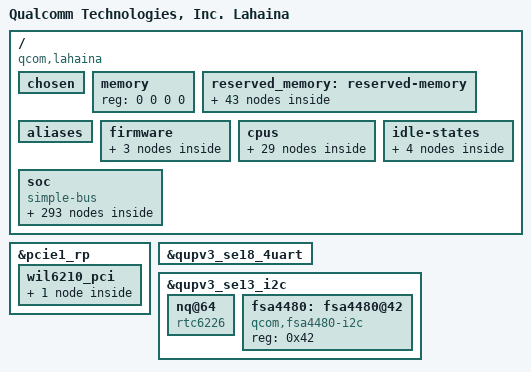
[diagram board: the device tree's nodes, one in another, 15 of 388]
// SPDX-License-Identifier: BSD-3-Clause
/*
 * Copyright (c) Qualcomm Technologies, Inc. and/or its subsidiaries.
 */

#include <dt-bindings/clock/qcom,aop-qmp.h>
#include <dt-bindings/clock/qcom,camcc-sm8350.h>
#include <dt-bindings/clock/qcom,dispcc-sm8350.h>
#include <dt-bindings/clock/qcom,gcc-sm8350.h>
#include <dt-bindings/clock/qcom,gpucc-sm8350.h>
#include <dt-bindings/clock/qcom,rpmh.h>
#include <dt-bindings/clock/qcom,sm8350-videocc.h>
#include <dt-bindings/interrupt-controller/arm-gic.h>
#include <dt-bindings/interconnect/qcom,icc.h>
#include <dt-bindings/interconnect/qcom,lahaina.h>
#include <dt-bindings/soc/qcom,ipcc.h>
#include <dt-bindings/soc/qcom,dcc_v2.h>
#include <dt-bindings/soc/qcom,rpmh-rsc.h>
#include <dt-bindings/spmi/spmi.h>
#include <dt-bindings/regulator/qcom,rpmh-regulator-levels.h>
#include <dt-bindings/gpio/gpio.h>


/ {
	model = "Qualcomm Technologies, Inc. Lahaina";
	compatible = "qcom,lahaina";
	qcom,msm-id = <415 0x10000>, <456 0x10000>, <501 0x10000>;
	interrupt-parent = <&intc>;

	#address-cells = <2>;
	#size-cells = <2>;

	chosen {
		bootargs = "loglevel=6 log_buf_len=512K rcupdate.rcu_expedited=1 printk.console_no_auto_verbose=1 rcu_nocbs=0-7 kpti=0 cpufreq.default_governor=performance pcie_ports=compat fw_devlink.strict=1 android_arch_task_struct_size=512 arm64.nosme sysctl.kernel.sched_pelt_multiplier=4 no-steal-acc swiotlb=0 loop.max_part=7 irqaffinity=0-1 kasan=off cgroup_disable=pressure sysctl.kernel.panic_on_rcu_stall=1 ftrace_dump_on_oops restrict_cma_redirect=false slub_debug=-";
		stdout-path = "/soc/qcom,qupv3_0_geni_se@9c0000/qcom,qup_uart@98c000:115200n8";
	};

	memory { device_type = "memory"; reg = <0 0 0 0>; };
	reserved_memory: reserved-memory { };

	aliases: aliases {
		ufshc1 = &ufshc_mem; /* Embedded UFS Slot */
		sdhc1 = &sdhc_2; /* SDC2 SD card slot */
		serial0 = &qupv3_se3_2uart;
		hsuart0 = &qupv3_se18_4uart;
		pci-domain0 = &pcie0; /* PCIe0 domain */
		pci-domain1 = &pcie1; /* PCIe1 domain */
		usb0 = &usb0;
		usb1 = &usb1;
	};

	firmware: firmware {
		qcom_scm: qcom_scm { };
	};

	cpus {
		#address-cells = <2>;
		#size-cells = <0>;

		CPU0: cpu@0 {
			device_type = "cpu";
			compatible = "qcom,kryo";
			reg = <0x0 0x0>;
			enable-method = "psci";
			cpu-release-addr = <0x0 0x90000000>;
			power-domains = <&CPU_PD0>;
			power-domain-names = "psci";
			qcom,freq-domain = <&cpufreq_hw 0 4>;
			capacity-dmips-mhz = <1024>;
			dynamic-power-coefficient = <100>;
			cpu-idle-states = <&SLVR_RAIL_OFF>;
			next-level-cache = <&L2_0>;
			#cooling-cells = <2>;
			L2_0: l2-cache {
			      compatible = "cache";
			      cache-level = <2>;
			      next-level-cache = <&L3_0>;

				L3_0: l3-cache {
				      compatible = "cache";
				      cache-level = <3>;
				};
			};
		};

		CPU1: cpu@100 {
			device_type = "cpu";
			compatible = "qcom,kryo";
			reg = <0x0 0x100>;
			enable-method = "psci";
			cpu-release-addr = <0x0 0x90000000>;
			power-domains = <&CPU_PD1>;
			power-domain-names = "psci";
			qcom,freq-domain = <&cpufreq_hw 0 4>;
			capacity-dmips-mhz = <1024>;
			dynamic-power-coefficient = <100>;
			cpu-idle-states = <&SLVR_RAIL_OFF>;
			next-level-cache = <&L2_1>;
			#cooling-cells = <2>;
			L2_1: l2-cache {
			      compatible = "cache";
			      cache-level = <2>;
			      next-level-cache = <&L3_0>;
			};
		};

		CPU2: cpu@200 {
			device_type = "cpu";
			compatible = "qcom,kryo";
			reg = <0x0 0x200>;
			enable-method = "psci";
			cpu-release-addr = <0x0 0x90000000>;
			power-domains = <&CPU_PD2>;
			power-domain-names = "psci";
			qcom,freq-domain = <&cpufreq_hw 0 4>;
			capacity-dmips-mhz = <1024>;
			dynamic-power-coefficient = <100>;
			cpu-idle-states = <&SLVR_RAIL_OFF>;
			next-level-cache = <&L2_2>;
			#cooling-cells = <2>;
			L2_2: l2-cache {
			      compatible = "cache";
			      cache-level = <2>;
			      next-level-cache = <&L3_0>;
			};
		};

		CPU3: cpu@300 {
			device_type = "cpu";
			compatible = "qcom,kryo";
			reg = <0x0 0x300>;
			enable-method = "psci";
			cpu-release-addr = <0x0 0x90000000>;
			power-domains = <&CPU_PD3>;
			power-domain-names = "psci";
			qcom,freq-domain = <&cpufreq_hw 0 4>;
			capacity-dmips-mhz = <1024>;
			dynamic-power-coefficient = <100>;
			cpu-idle-states = <&SLVR_RAIL_OFF>;
			next-level-cache = <&L2_3>;
			#cooling-cells = <2>;
			L2_3: l2-cache {
			      compatible = "cache";
			      cache-level = <2>;
			      next-level-cache = <&L3_0>;
			};
		};

		CPU4: cpu@400 {
			device_type = "cpu";
			compatible = "qcom,kryo";
			reg = <0x0 0x400>;
			enable-method = "psci";
			cpu-release-addr = <0x0 0x90000000>;
			power-domains = <&CPU_PD4>;
			power-domain-names = "psci";
			qcom,freq-domain = <&cpufreq_hw 1 4>;
			capacity-dmips-mhz = <1946>;
			dynamic-power-coefficient = <515>;
			cpu-idle-states = <&GOLD_RAIL_OFF>;
			next-level-cache = <&L2_4>;
			#cooling-cells = <2>;
			L2_4: l2-cache {
			      compatible = "cache";
			      cache-level = <2>;
			      next-level-cache = <&L3_0>;
			};
		};

		CPU5: cpu@500 {
			device_type = "cpu";
			compatible = "qcom,kryo";
			reg = <0x0 0x500>;
			enable-method = "psci";
			cpu-release-addr = <0x0 0x90000000>;
			power-domains = <&CPU_PD5>;
			power-domain-names = "psci";
			qcom,freq-domain = <&cpufreq_hw 1 4>;
			capacity-dmips-mhz = <1946>;
			dynamic-power-coefficient = <515>;
			cpu-idle-states = <&GOLD_RAIL_OFF>;
			next-level-cache = <&L2_5>;
			#cooling-cells = <2>;
			L2_5: l2-cache {
			      compatible = "cache";
			      cache-level = <2>;
			      next-level-cache = <&L3_0>;
			};
		};

		CPU6: cpu@600 {
			device_type = "cpu";
			compatible = "qcom,kryo";
			reg = <0x0 0x600>;
			enable-method = "psci";
			cpu-release-addr = <0x0 0x90000000>;
			power-domains = <&CPU_PD6>;
			power-domain-names = "psci";
			qcom,freq-domain = <&cpufreq_hw 1 4>;
			capacity-dmips-mhz = <1946>;
			dynamic-power-coefficient = <515>;
			cpu-idle-states = <&GOLD_RAIL_OFF>;
			next-level-cache = <&L2_6>;
			#cooling-cells = <2>;
			L2_6: l2-cache {
			      compatible = "cache";
			      cache-level = <2>;
			      next-level-cache = <&L3_0>;
			};
		};

		CPU7: cpu@700 {
			device_type = "cpu";
			compatible = "qcom,kryo";
			reg = <0x0 0x700>;
			enable-method = "psci";
			cpu-release-addr = <0x0 0x90000000>;
			power-domains = <&CPU_PD7>;
			power-domain-names = "psci";
			qcom,freq-domain = <&cpufreq_hw 2 4>;
			capacity-dmips-mhz = <2048>;
			dynamic-power-coefficient = <845>;
			cpu-idle-states = <&GOLD_RAIL_OFF>;
			next-level-cache = <&L2_7>;
			#cooling-cells = <2>;
			L2_7: l2-cache {
			      compatible = "cache";
			      cache-level = <2>;
			      next-level-cache = <&L3_0>;
			};
		};

		cpu-map {
			cluster0 {
				core0 {
					cpu = <&CPU0>;
				};

				core1 {
					cpu = <&CPU1>;
				};

				core2 {
					cpu = <&CPU2>;
				};

				core3 {
					cpu = <&CPU3>;
				};
			};

			cluster1 {
				core0 {
					cpu = <&CPU4>;
				};

				core1 {
					cpu = <&CPU5>;
				};

				core2 {
					cpu = <&CPU6>;
				};
			};

			cluster2 {

				core0 {
					cpu = <&CPU7>;
				};
			};
		};
	};

	idle-states {
		SILVER_OFF: silver-c4 {  /* C4 */
			compatible = "arm,idle-state";
			idle-state-name = "rail-pc";
			entry-latency-us = <360>;
			exit-latency-us = <531>;
			min-residency-us = <3934>;
			arm,psci-suspend-param = <0x40000004>;
			local-timer-stop;
		};

		GOLD_OFF: gold-c4 {  /* C4 */
			compatible = "arm,idle-state";
			idle-state-name = "rail-pc";
			entry-latency-us = <702>;
			exit-latency-us = <1061>;
			min-residency-us = <4488>;
			arm,psci-suspend-param = <0x40000004>;
			local-timer-stop;
		};

		CLUSTER_PWR_DN: cluster-d4 { /* D4 */
			compatible = "domain-idle-state";
			entry-latency-us = <2752>;
			exit-latency-us = <3048>;
			min-residency-us = <6118>;
			arm,psci-suspend-param = <0x41000044>;
		};

		CLUSTER_SLEEP_AOSS_SLEEP: cluster-sleep-1 {
			compatible = "domain-idle-state";
			entry-latency-us = <3263>;
			exit-latency-us = <6562>;
			min-residency-us = <9987>;
			arm,psci-suspend-param = <0x4100c344>;
		};
	};

soc: soc { };

};


&firmware {
	qcom_scm {
		compatible = "qcom,scm";
		qcom,dload-mode = <&tcsr 0x13000>;
	};
	qcom_smcinvoke {
		compatible = "qcom,smcinvoke";
	};

	qcom_mem_object {
		compatible = "qcom,mem-object";
	};
};

&reserved_memory {
	#address-cells = <2>;
	#size-cells = <2>;
	ranges;

	hyp_mem: hyp_region@80000000 {
		no-map;
		reg = <0x0 0x80000000 0x0 0x600000>;
	};

	xbl_aop_mem: xbl_aop_region@80700000 {
		no-map;
		reg = <0x0 0x80700000 0x0 0x160000>;
	};

	cmd_db: reserved-memory@80860000 {
		compatible = "qcom,cmd-db";
		no-map;
		reg = <0x0 0x80860000 0x0 0x20000>;
	};

	reserved_xbl_uefi_log: res_xbl_uefi_log_region@80880000 {
		no-map;
		reg = <0x0 0x80880000 0x0 0x14000>;
	};

	smem_mem: smem_region@80900000 {
		no-map;
		reg = <0x0 0x80900000 0x0 0x200000>;
	};

	cpucp_fw_mem: cpucp_fw_region@80b00000 {
		no-map;
		reg = <0x0 0x80b00000 0x0 0x100000>;
	};

	cdsp_secure_heap_mem: cdsp_secure_heap@80c00000 {
		no-map;
		reg = <0x0 0x80c00000 0x0 0x4600000>;
	};

	pil_camera_mem: pil_camera_region@85200000 {
		no-map;
		reg = <0x0 0x85200000 0x0 0x500000>;
	};


	pil_cvp_mem: pil_cvp_region@85c00000 {
		no-map;
		reg = <0x0 0x85c00000 0x0 0x500000>;
	};

	pil_adsp_mem: pil_adsp_region@86100000 {
		no-map;
		reg = <0x0 0x86100000 0x0 0x2100000>;
	};

	pil_slpi_mem: pil_slpi_region@88200000 {
		no-map;
		reg = <0x0 0x88200000 0x0 0x1500000>;
	};

	pil_cdsp_mem: pil_cdsp_region@89700000 {
		no-map;
		reg = <0x0 0x89700000 0x0 0x1e00000>;
	};

	pil_ipa_fw_mem: pil_ipa_fw_region@8b500000 {
		no-map;
		reg = <0x0 0x8b500000 0x0 0x10000>;
	};

	pil_ipa_gsi_mem: pil_ipa_gsi_region@8b510000 {
		no-map;
		reg = <0x0 0x8b510000 0x0 0xa000>;
	};

	pil_gpu_mem: pil_gpu_region@8b51a000 {
		no-map;
		reg = <0x0 0x8b51a000 0x0 0x2000>;
	};

    /* First part of the "SPU secure shared memory" region */
	spu_tz_shared_mem: spu_secure_shared_memory_region@8B580000 {
		no-map;
		reg = <0x0 0x8B580000 0x0 0x40000>;
	};

	pil_spss_mem: pil_spss_region@8b600000 {
		no-map;
		reg = <0x0 0x8b600000 0x0 0x100000>;
	};

	pil_modem_mem: modem_region@8b800000 {
		no-map;
		reg = <0x0 0x8b800000 0x0 0x10000000>;
	};

	hyp_reserved_mem: qheebsp_dbg_vm_hyp_region@d0000000 {
		no-map;
		reg = <0x0 0xd0000000 0x0 0x800000>;
	};

	pil_trustedvm_mem: pil_trustedvm_region@d0800000 {
		no-map;
		reg = <0x0 0xd0800000 0x0 0x76f7000>;
	};

	qrtr_shbuf: qrtr-shmem {
		no-map;
		reg = <0x0 0xd7ef7000 0x0 0x9000>;
	};

	pil_video_mem: pil_video_region@9b800000 {
		no-map;
		reg = <0x0 0x9b800000 0x0 0x700000>;
	};

	chan0_shbuf: neuron_block@0 {
		no-map;
		reg = <0x0 0xd7f00000 0x0 0x80000>;
	};

	chan1_shbuf: neuron_block@1 {
		no-map;
		reg = <0x0 0xd7f80000 0x0 0x80000>;
	};

	removed_mem: removed_region@d8800000 {
		no-map;
		reg = <0x0 0xd8800000 0x0 0x6800000>;
	};

	adsp_mem: adsp_region {
		compatible = "shared-dma-pool";
		alloc-ranges = <0x0 0x00000000 0x0 0xffffffff>;
		reusable;
		alignment = <0x0 0x400000>;
		size = <0x0 0xC00000>;
	};

	sdsp_mem: sdsp_region {
		compatible = "shared-dma-pool";
		alloc-ranges = <0x0 0x00000000 0x0 0xffffffff>;
		reusable;
		alignment = <0x0 0x400000>;
		size = <0x0 0x800000>;
	};

	cdsp_mem: cdsp_region {
		compatible = "shared-dma-pool";
		alloc-ranges = <0x0 0x00000000 0x0 0xffffffff>;
		reusable;
		alignment = <0x0 0x400000>;
		size = <0x0 0x400000>;
	};

	user_contig_mem: user_contig_region {
		compatible = "shared-dma-pool";
		alloc-ranges = <0x0 0x00000000 0x0 0xffffffff>;
		reusable;
		alignment = <0x0 0x400000>;
		size = <0x0 0x1000000>;
	};

	qseecom_mem: qseecom_region {
		compatible = "shared-dma-pool";
		alloc-ranges = <0x0 0x00000000 0x0 0xffffffff>;
		reusable;
		alignment = <0x0 0x400000>;
		size = <0x0 0x1400000>;
	};

	qseecom_ta_mem: qseecom_ta_region {
		compatible = "shared-dma-pool";
		alloc-ranges = <0x0 0x00000000 0x0 0xffffffff>;
		reusable;
		alignment = <0x0 0x400000>;
		size = <0x0 0x1000000>;
	};

	secure_display_memory: secure_display_region { /* Secure UI */
		compatible = "shared-dma-pool";
		alloc-ranges = <0x0 0x00000000 0x0 0xffffffff>;
		reusable;
		alignment = <0x0 0x400000>;
		size = <0x0 0xA400000>;
	};

	cnss_wlan_mem: cnss_wlan_region {
		compatible = "shared-dma-pool";
		alloc-ranges = <0x0 0x00000000 0x0 0xffffffff>;
		reusable;
		alignment = <0x0 0x400000>;
		size = <0x0 0x1400000>;
	};

	/* global autoconfigured region for contiguous allocations */
	system_cma: linux,cma {
		compatible = "shared-dma-pool";
		alloc-ranges = <0x0 0x00000000 0x0 0xdfffffff>;
		reusable;
		alignment = <0x0 0x400000>;
		size = <0x0 0x2000000>;
		linux,cma-default;
	};

	sp_mem: sp_region {  /* SPSS-HLOS ION shared mem */
		compatible = "shared-dma-pool";
		alloc-ranges = <0x0 0x00000000 0x0 0xffffffff>;
		reusable;
		alignment = <0x0 0x400000>;
		size = <0x0 0x1000000>;
	};

	kinfo_mem: debug_kinfo_region {
		alloc-ranges = <0x0 0x00000000 0xffffffff 0xffffffff>;
		size = <0x0 0x1000>;
		no-map;
	};

	va_md_mem: va_md_mem_region {
		compatible = "shared-dma-pool";
		alloc-ranges = <0x0 0x00000000 0x0 0xffffffff>;
		reusable;
		size = <0 0x1000000>;
	};

	audio_cma_mem: audio_cma_region {
		compatible = "shared-dma-pool";
		alloc-ranges = <0x0 0x00000000 0x0 0xffffffff>;
		reusable;
		alignment = <0x0 0x400000>;
		size = <0x0 0x1C00000>;
	};

	/*
	 * Demura memory regions are to be commented out if
	 * feature not in use.
	 */
	demura_memory_0: demura_region_0 {
		reg = <0x0 0x0 0x0 0x0>;
		label = "demura hfc region 0";
	};

	demura_memory_1: demura_region_1 {
		reg = <0x0 0x0 0x0 0x0>;
		label = "demura hfc region 1";
	};

	dfps_data_memory: dfps_data_region {
		reg = <0x0 0xe3300000 0x0 0x0100000>;
		label = "dfps_data_region";
	};

	memshare_mem: memshare_region {
		compatible = "shared-dma-pool";
		no-map;
		/*
		 * Memory shared with modem needs to be outside of
		 * the CLADE address space, which begins at
		 * 0xE0000000 and spans 512 MB.
		 */
		alloc-ranges = <0x0 0x00000000 0x0 0xdfffffff>;
		alignment = <0x0 0x100000>;
		size = <0x0 0x800000>;
	};

	non_secure_display_memory: non_secure_display_region {
		compatible = "shared-dma-pool";
		alloc-ranges = <0x0 0x00000000 0x0 0xffffffff>;
		reusable;
		alignment = <0x0 0x400000>;
		size = <0x0 0x6400000>;
	};
};

&soc {
	#address-cells = <1>;
	#size-cells = <1>;
	ranges = <0 0 0 0xffffffff>;
	compatible = "simple-bus";

	psci {
		compatible = "arm,psci-1.0";
		method = "smc";
		CPU_PD0: cpu-pd0 {
			#power-domain-cells = <0>;
			power-domains = <&CLUSTER_PD>;
		};

		CPU_PD1: cpu-pd1 {
			#power-domain-cells = <0>;
			power-domains = <&CLUSTER_PD>;
		};

		CPU_PD2: cpu-pd2 {
			#power-domain-cells = <0>;
			power-domains = <&CLUSTER_PD>;
		};

		CPU_PD3: cpu-pd3 {
			#power-domain-cells = <0>;
			power-domains = <&CLUSTER_PD>;
		};

		CPU_PD4: cpu-pd4 {
			#power-domain-cells = <0>;
			power-domains = <&CLUSTER_PD>;
		};

		CPU_PD5: cpu-pd5 {
			#power-domain-cells = <0>;
			power-domains = <&CLUSTER_PD>;
		};

		CPU_PD6: cpu-pd6 {
			#power-domain-cells = <0>;
			power-domains = <&CLUSTER_PD>;
		};

		CPU_PD7: cpu-pd7 {
			#power-domain-cells = <0>;
			power-domains = <&CLUSTER_PD>;
		};

		CLUSTER_PD: cluster-pd {
			#power-domain-cells = <0>;
			domain-idle-states = <&CLUSTER_PWR_DN &CLUSTER_SLEEP_AOSS_SLEEP>;
		};

	};

	cluster-device {
		compatible = "qcom,lpm-cluster-dev";
		power-domains = <&CLUSTER_PD>;
	};

	sram@c3f0000 {
		compatible = "qcom,rpmh-stats";
		reg = <0x0c3f0000 0x400>;
		ss-name = "modem", "adsp", "adsp_island",
			  "cdsp", "apss", "slpi", "slpi_island";
	};

	apps_rsc: rsc@18200000 {
		label = "apps_rsc";
		compatible = "qcom,rpmh-rsc";
		reg = <0x18200000 0x10000>,
		      <0x18210000 0x10000>,
		      <0x18220000 0x10000>;
		reg-names = "drv-0", "drv-1", "drv-2";
		interrupts = <GIC_SPI 3 IRQ_TYPE_LEVEL_HIGH>,
			     <GIC_SPI 4 IRQ_TYPE_LEVEL_HIGH>,
			     <GIC_SPI 5 IRQ_TYPE_LEVEL_HIGH>;
		qcom,drv-count = <3>;
		power-domains = <&CLUSTER_PD>;
		apps_rsc_drv2: drv@2 {
			qcom,tcs-offset = <0xd00>;
			qcom,drv-id = <2>;
			channel@0 {
				qcom,tcs-config = <ACTIVE_TCS  2>,
						<SLEEP_TCS   3>,
						<WAKE_TCS    3>,
						<CONTROL_TCS 0>,
						<FAST_PATH_TCS 0>;
			};

			apps_bcm_voter: bcm_voter {
				compatible = "qcom,bcm-voter";
			};

			rpmhcc: qcom,rpmhclk {
				compatible = "qcom,sm8350-rpmh-clk";
				#clock-cells = <1>;
			};
		};
	};

	disp_rsc: rsc@af20000 {
		label = "disp_rsc";
		compatible = "qcom,rpmh-rsc";
		reg = <0xaf20000 0x10000>;
		reg-names = "drv-0";
		interrupts = <GIC_SPI 129 IRQ_TYPE_LEVEL_HIGH>;
		qcom,drv-count = <1>;

		disp_rsc_drv0: drv@0 {
			qcom,tcs-offset = <0x1c00>;
			qcom,drv-id = <0>;
			channel@0 {
				qcom,tcs-config = <ACTIVE_TCS  0>,
					  <SLEEP_TCS   1>,
					  <WAKE_TCS    1>,
					  <CONTROL_TCS 0>,
					  <FAST_PATH_TCS 0>;
			};

			disp_bcm_voter: bcm_voter {
				compatible = "qcom,bcm-voter";
				qcom,tcs-wait = <QCOM_ICC_TAG_AMC>;
			};
		};
	};

	slimbam: bamdma@3a84000 {
		compatible = "qcom,bam-v1.7.0";
		reg = <0x03a84000 0x20000>;
		interrupts = <GIC_SPI 164 IRQ_TYPE_LEVEL_HIGH>;
		#dma-cells = <1>;
		qcom,controlled-remotely;
		num-channels = <31>;
		qcom,ee = <1>;
		qcom,num-ees = <2>;
		iommus = <&apps_smmu 0x1826 0x0>;
	};

	slim_msm: slim@3ac0000 {
		compatible = "qcom,slim-ngd-v1.5.0";
		reg = <0x03ac0000 0x2c000>;
		interrupts = <GIC_SPI 163 IRQ_TYPE_LEVEL_HIGH>;
		qcom,apps-ch-pipes = <0x0>;
		qcom,ea-pc = <0x350>;
		dmas = <&slimbam 3>, <&slimbam 4>;
		dma-names = "rx", "tx";
		iommus = <&apps_smmu 0x1826 0x0>;
		qcom,wait_for_adsp_up;
		#address-cells = <1>;
		#size-cells = <0>;
		status = "okay";
		ngd@1 {
			reg = <1>;
			#address-cells = <1>;
			#size-cells = <1>;

			/* slimbus child nodes */
			slimbus: btfmslim-driver {
				compatible = "slim217,221";
				reg = <1 0>;
			};
		};
	};

	intc: interrupt-controller@17a00000 {
		compatible = "arm,gic-v3";
		#interrupt-cells = <3>;
		interrupt-controller;
		#redistributor-regions = <1>;
		redistributor-stride = <0x0 0x20000>;
		reg = <0x17a00000 0x10000>,     /* GICD */
		      <0x17a60000 0x100000>;    /* GICR * 8 */
		interrupts = <GIC_PPI 9 IRQ_TYPE_LEVEL_HIGH>;
	};

	arch_timer: timer {
		compatible = "arm,armv8-timer";
		interrupts = <GIC_PPI 13 (GIC_CPU_MASK_SIMPLE(8) | IRQ_TYPE_LEVEL_LOW)>,
			     <GIC_PPI 14 (GIC_CPU_MASK_SIMPLE(8) | IRQ_TYPE_LEVEL_LOW)>,
			     <GIC_PPI 11 (GIC_CPU_MASK_SIMPLE(8) | IRQ_TYPE_LEVEL_LOW)>,
			     <GIC_PPI 12 (GIC_CPU_MASK_SIMPLE(8) | IRQ_TYPE_LEVEL_LOW)>;
		clock-frequency = <19200000>;
	};

	memtimer: timer@17c20000 {
		#address-cells = <1>;
		#size-cells = <1>;
		ranges;
		compatible = "arm,armv7-timer-mem";
		reg = <0x17c20000 0x1000>;
		clock-frequency = <19200000>;

		frame@17c21000 {
			frame-number = <0>;
			interrupts = <GIC_SPI 8 IRQ_TYPE_LEVEL_HIGH>,
				     <GIC_SPI 6 IRQ_TYPE_LEVEL_HIGH>;
			reg = <0x17c21000 0x1000>,
			      <0x17c22000 0x1000>;
		};

		frame@17c23000 {
			frame-number = <1>;
			interrupts = <GIC_SPI 9 IRQ_TYPE_LEVEL_HIGH>;
			reg = <0x17c23000 0x1000>;
			status = "disabled";
		};

		frame@17c25000 {
			frame-number = <2>;
			interrupts = <GIC_SPI 10 IRQ_TYPE_LEVEL_HIGH>;
			reg = <0x17c25000 0x1000>;
			status = "disabled";
		};

		frame@17c27000 {
			frame-number = <3>;
			interrupts = <GIC_SPI 11 IRQ_TYPE_LEVEL_HIGH>;
			reg = <0x17c27000 0x1000>;
			status = "disabled";
		};

		frame@17c29000 {
			frame-number = <4>;
			interrupts = <GIC_SPI 12 IRQ_TYPE_LEVEL_HIGH>;
			reg = <0x17c29000 0x1000>;
			status = "disabled";
		};

		frame@17c2b000 {
			frame-number = <5>;
			interrupts = <GIC_SPI 13 IRQ_TYPE_LEVEL_HIGH>;
			reg = <0x17c2b000 0x1000>;
			status = "disabled";
		};

		frame@17c2d000 {
			frame-number = <6>;
			interrupts = <GIC_SPI 14 IRQ_TYPE_LEVEL_HIGH>;
			reg = <0x17c2d000 0x1000>;
			status = "disabled";
		};
	};

	cpu_pmu: cpu-pmu {
		compatible = "arm,armv8-pmuv3";
		qcom,irq-is-percpu;
		interrupts = <GIC_PPI 7 IRQ_TYPE_LEVEL_HIGH>;
	};

	google,debug-kinfo {
		compatible = "google,debug-kinfo";
		memory-region = <&kinfo_mem>;
	};

	qcom,msm-imem@146bf000 {
		compatible = "qcom,msm-imem";
		reg = <0x146bf000 0x1000>;
		ranges = <0x0 0x146bf000 0x1000>;
		#address-cells = <1>;
		#size-cells = <1>;

		mem_dump_table@10 {
			compatible = "qcom,msm-imem-mem_dump_table";
			reg = <0x10 0x8>;
		};

		restart_reason@65c {
			compatible = "qcom,msm-imem-restart_reason";
			reg = <0x65c 0x4>;
		};

		dload_type@1c {
			compatible = "qcom,msm-imem-dload-type";
			reg = <0x1c 0x4>;
		};

		boot_stats@6b0 {
			compatible = "qcom,msm-imem-boot_stats";
			reg = <0x6b0 0x20>;
		};

		kaslr_offset@6d0 {
			compatible = "qcom,msm-imem-kaslr_offset";
			reg = <0x6d0 0xc>;
		};

		pil@94c {
			compatible = "qcom,msm-imem-pil";
			reg = <0x94c 0xc8>;
		};

		pil@6dc {
			compatible = "qcom,msm-imem-pil-disable-timeout";
			reg = <0x6dc 0x4>;
		};

		diag_dload@c8 {
			compatible = "qcom,msm-imem-diag-dload";
			reg = <0xc8 0xc8>;
		};
	};

	tlmm: pinctrl@f000000 {
		compatible = "qcom,lahaina-tlmm";
		reg = <0x0F000000 0x1000000>;
		interrupts = <GIC_SPI 208 IRQ_TYPE_LEVEL_HIGH>;
		gpio-controller;
		#gpio-cells = <2>;
		interrupt-controller;
		#interrupt-cells = <2>;
		wakeup-parent = <&pdc>;
	};

	ipcc_mproc: qcom,ipcc@408000 {
		compatible = "qcom,ipcc";
		reg = <0x408000 0x1000>;
		interrupts = <GIC_SPI 229 IRQ_TYPE_LEVEL_HIGH>;
		interrupt-controller;
		#interrupt-cells = <3>;
		#mbox-cells = <2>;
	};

	qcom,svm_neuron_block {
		compatible = "qcom,neuron-service";
		#address-cells = <1>;
		#size-cells = <0>;
		protocol {
			compatible = "qcom,neuron-protocol-block";
			processes = "server";
		};

		application {
			compatible = "qcom,neuron-block-server";
		};

		channel@0 {
			compatible = "qcom,neuron-channel-haven-shmem";
			reg = <0>;
			class = "message-queue";
			direction = "receive";
			max-size = <0 65536>;
			shared-buffer = <&chan0_shbuf>;
			qcom,primary;
			haven-label = <1>;
			peer-name = <2>;
		};

		channel@1 {
			compatible = "qcom,neuron-channel-haven-shmem";
			reg = <1>;
			class = "message-queue";
			direction = "send";
			max-size = <0 65536>;
			shared-buffer = <&chan1_shbuf>;
			qcom,primary;
			haven-label = <2>;
			peer-name = <2>;
		};
	};

	qcom,qsee_ipc_irq_bridge {
		compatible = "qcom,qsee-ipc-irq-bridge";

		qcom,qsee-ipc-irq-spss {
			qcom,dev-name = "qsee_ipc_irq_spss";
			interrupt-parent = <&ipcc_mproc>;
			interrupts = <IPCC_CLIENT_SPSS
				      IPCC_MPROC_SIGNAL_TZ
				      IRQ_TYPE_EDGE_RISING>;
			label = "spss";
		};
	};

	qrtr-haven {
		compatible = "qcom,qrtr-haven";
		qcom,master;
		haven-label = <3>;
		peer-name = <2>;
		shared-buffer = <&qrtr_shbuf>;
	};

	qcom,memshare {
		compatible = "qcom,memshare";

		qcom,client_1 {
			compatible = "qcom,memshare-peripheral";
			qcom,peripheral-size = <0x0>;
			qcom,client-id = <0>;
			qcom,allocate-boot-time;
			label = "modem";
		};

		qcom,client_2 {
			compatible = "qcom,memshare-peripheral";
			qcom,peripheral-size = <0x0>;
			qcom,client-id = <2>;
			label = "modem";
		};

		qcom,client_3 {
			compatible = "qcom,memshare-peripheral";
			qcom,peripheral-size = <0x500000>;
			memory-region = <&memshare_mem>;
			qcom,client-id = <1>;
			qcom,allocate-on-request;
			label = "modem";
		};
	};

	clocks {
		xo_board: xo-board {
			compatible = "fixed-clock";
			#clock-cells = <0>;
			clock-frequency = <38400000>;
			clock-output-names = "xo_board";
		};

		sleep_clk: sleep-clk {
			compatible = "fixed-clock";
			#clock-cells = <0>;
			clock-frequency = <32000>;
			clock-output-names = "sleep_clk";
		};

		pcie_0_pipe_clk: pcie-0-pipe-clk {
			compatible = "fixed-clock";
			clock-frequency = <1000>;
			clock-output-names = "pcie_0_pipe_clk";
			#clock-cells = <0>;
		};

		pcie_1_pipe_clk: pcie-1-pipe-clk {
			compatible = "fixed-clock";
			clock-frequency = <1000>;
			clock-output-names = "pcie_1_pipe_clk";
			#clock-cells = <0>;
		};

		usb3_phy_wrapper_gcc_usb30_pipe_clk: usb3-phy-wrapper-gcc-usb30-pipe-clk {
			compatible = "fixed-clock";
			clock-frequency = <1000>;
			clock-output-names = "usb3_phy_wrapper_gcc_usb30_pipe_clk";
			#clock-cells = <0>;
		};

		ufs_card_rx_symbol_0_clk: ufs_card_rx_symbol_0_clk {
			compatible = "fixed-clock";
			clock-frequency = <1000>;
			clock-output-names = "ufs_card_rx_symbol_0_clk";
			#clock-cells = <0>;
		};

		ufs_card_rx_symbol_1_clk: ufs_card_rx_symbol_1_clk {
			compatible = "fixed-clock";
			clock-frequency = <1000>;
			clock-output-names = "ufs_card_rx_symbol_1_clk";
			#clock-cells = <0>;
		};

		ufs_card_tx_symbol_0_clk: ufs_card_tx_symbol_0_clk {
			compatible = "fixed-clock";
			clock-frequency = <1000>;
			clock-output-names = "ufs_card_tx_symbol_0_clk";
			#clock-cells = <0>;
		};

		ufs_phy_rx_symbol_0_clk: ufs_phy_rx_symbol_0_clk {
			compatible = "fixed-clock";
			clock-frequency = <1000>;
			clock-output-names = "ufs_phy_rx_symbol_0_clk";
			#clock-cells = <0>;
		};

		ufs_phy_rx_symbol_1_clk: ufs_phy_rx_symbol_1_clk {
			compatible = "fixed-clock";
			clock-frequency = <1000>;
			clock-output-names = "ufs_phy_rx_symbol_1_clk";
			#clock-cells = <0>;
		};

		ufs_phy_tx_symbol_0_clk: ufs_phy_tx_symbol_0_clk {
			compatible = "fixed-clock";
			clock-frequency = <1000>;
			clock-output-names = "ufs_phy_tx_symbol_0_clk";
			#clock-cells = <0>;
		};

		usb3_uni_phy_sec_gcc_usb30_pipe_clk: usb3_uni_phy_sec_gcc_usb30_pipe_clk {
			compatible = "fixed-clock";
			clock-frequency = <1000>;
			clock-output-names = "usb3_uni_phy_sec_gcc_usb30_pipe_clk";
			#clock-cells = <0>;
		};

	};

	gcc: clock-controller@100000 {
		compatible = "qcom,gcc-sm8350", "syscon";
		reg = <0x100000 0x1f0000>;
		reg-names = "cc_base";
		vdd_cx-supply = <&VDD_CX_LEVEL>;
		clocks = <&rpmhcc RPMH_CXO_CLK>,
				<&sleep_clk>,
				<&pcie_0_pipe_clk>, <&pcie_1_pipe_clk>,
				<&usb3_phy_wrapper_gcc_usb30_pipe_clk>,
				<&ufs_card_rx_symbol_0_clk>, <&ufs_card_rx_symbol_1_clk>,
				<&ufs_card_tx_symbol_0_clk>, <&ufs_phy_rx_symbol_0_clk>,
				<&ufs_phy_rx_symbol_1_clk>, <&ufs_phy_tx_symbol_0_clk>,
				<&usb3_uni_phy_sec_gcc_usb30_pipe_clk>;
		clock-names = "bi_tcxo",
				"sleep_clk",
				"pcie_0_pipe_clk", "pcie_1_pipe_clk",
				"usb3_phy_wrapper_gcc_usb30_pipe_clk",
				"ufs_card_rx_symbol_0_clk", "ufs_card_rx_symbol_1_clk",
				"ufs_card_tx_symbol_0_clk", "ufs_phy_rx_symbol_0_clk",
				"ufs_phy_rx_symbol_1_clk", "ufs_phy_tx_symbol_0_clk",
				"usb3_uni_phy_sec_gcc_usb30_pipe_clk";
		#clock-cells = <1>;
		#reset-cells = <1>;
	};

	videocc: clock-controller@abf0000 {
		compatible = "qcom,sm8350-videocc", "syscon";
		reg = <0xabf0000 0x10000>;
		reg-name = "cc_base";
		vdd_mm-supply = <&VDD_MM_LEVEL>;
		vdd_mx-supply = <&VDD_MXA_LEVEL>;
		clocks = <&rpmhcc RPMH_CXO_CLK>, <&rpmhcc RPMH_CXO_CLK_A>,
			<&sleep_clk>;
		clock-names = "bi_tcxo", "bi_tcxo_ao", "sleep_clk";
		#clock-cells = <1>;
		#reset-cells = <1>;
	};

	camcc: clock-controller@ad00000 {
		compatible = "qcom,sm8350-camcc", "syscon";
		reg = <0xad00000 0x10000>;
		reg-names = "cc_base";
		vdd_mm-supply = <&VDD_MM_LEVEL>;
		vdd_mx-supply = <&VDD_MXA_LEVEL>;
		clocks = <&rpmhcc RPMH_CXO_CLK>, <&rpmhcc RPMH_CXO_CLK_A>,
			<&sleep_clk>;
		clock-names = "bi_tcxo", "bi_tcxo_ao", "sleep_clk";
		#clock-cells = <1>;
		#reset-cells = <1>;
	};

	dispcc: clock-controller@af00000 {
		compatible = "qcom,sm8350-dispcc", "syscon";
		reg = <0xaf00000 0x20000>;
		reg-name = "cc_base";
		vdd_mm-supply = <&VDD_MM_LEVEL>;
		clocks = <&rpmhcc RPMH_CXO_CLK>, <&rpmhcc RPMH_CXO_CLK_A>,
			<&sleep_clk>;
		clock-names = "bi_tcxo", "bi_tcxo_ao", "sleep_clk";
		#clock-cells = <1>;
		#reset-cells = <1>;
	};

	gpucc: clock-controller@3d90000 {
		compatible = "qcom,sm8350-gpucc", "syscon";
		reg = <0x3d90000 0x9000>;
		reg-names = "cc_base";
		vdd_mx-supply = <&VDD_MXA_LEVEL>;
		vdd_cx-supply = <&VDD_CX_LEVEL>;
		clocks = <&rpmhcc RPMH_CXO_CLK>, <&gcc GCC_GPU_GPLL0_CLK_SRC>,
			<&gcc GCC_GPU_GPLL0_DIV_CLK_SRC>;
		clock-names = "bi_tcxo", "gcc_gpu_gpll0_clk_src",
			"gcc_gpu_gpll0_div_clk_src";
		#clock-cells = <1>;
		#reset-cells = <1>;
	};

	apsscc: syscon@182a0000 {
		compatible = "syscon";
		reg = <0x182a0000 0x1c>;
	};

	mccc: syscon@90ba000 {
		compatible = "syscon";
		reg = <0x90ba000 0x54>;
	};

	debugcc: debug-clock-controller@0 {
		compatible = "qcom,sm8350-debugcc";
		qcom,gcc = <&gcc>;
		qcom,videocc = <&videocc>;
		qcom,dispcc = <&dispcc>;
		qcom,camcc = <&camcc>;
		qcom,gpucc = <&gpucc>;
		qcom,apsscc = <&apsscc>;
		qcom,mccc = <&mccc>;
		clocks = <&rpmhcc RPMH_CXO_CLK>,
			 <&camcc 0>,
			 <&dispcc 0>,
			 <&gcc 0>,
			 <&gpucc 0>,
			 <&videocc 0>;
		clock-names = "xo_clk_src",
			      "camcc",
			      "dispcc",
			      "gcc",
			      "gpucc",
			      "videocc";
		#clock-cells = <1>;
	};

	cpufreq_hw: qcom,cpufreq-hw {
		compatible = "qcom,cpufreq-epss";
		reg = <0x18591000 0x1000>, <0x18592000 0x1000>,
			<0x18593000 0x1000>;
		reg-names = "freq-domain0", "freq-domain1",
				"freq-domain2";

		clocks = <&rpmhcc RPMH_CXO_CLK>, <&gcc GCC_GPLL0>;
		clock-names = "xo", "alternate";

		qcom,lut-row-size = <4>;
		qcom,skip-enable-check;

		interrupts = <GIC_SPI 30 IRQ_TYPE_LEVEL_HIGH>,
				<GIC_SPI 31 IRQ_TYPE_LEVEL_HIGH>,
				<GIC_SPI 19 IRQ_TYPE_LEVEL_HIGH>;
		interrupt-names = "dcvsh0_int", "dcvsh1_int", "dcvsh2_int";

		#freq-domain-cells = <2>;
	};

	qcom,cpufreq-hw-debug@18591000 {
		compatible = "qcom,cpufreq-hw-epss-debug";
		reg = <0x18591000 0x800>;
		reg-names = "domain-top";
		qcom,freq-hw-domain = <&cpufreq_hw 0>, <&cpufreq_hw 1>,
					<&cpufreq_hw 2>;
	};

	dload_mode {
		compatible = "qcom,dload-mode";
	};

	mini_dump_mode {
		compatible = "qcom,minidump";
		status = "ok";
	};

	va_mini_dump {
		compatible = "qcom,va-minidump";
		memory-region = <&va_md_mem>;
		status = "ok";
	};

	logbuf: qcom,logbuf-vendor-hooks {
		compatible = "qcom,logbuf-vendor-hooks";
	};

	/* CAM_CC GDSCs */
	cam_cc_bps_gdsc: qcom,gdsc@ad07004 {
		compatible = "qcom,gdsc";
		reg = <0xad07004 0x4>;
		regulator-name = "cam_cc_bps_gdsc";
		qcom,gds-timeout = <500>;
		parent-supply = <&VDD_MM_LEVEL>;
		vdd_parent-supply = <&VDD_MM_LEVEL>;
		qcom,support-hw-trigger;
		qcom,retain-regs;
	};

	cam_cc_ife_0_gdsc: qcom,gdsc@ad0a004 {
		compatible = "qcom,gdsc";
		reg = <0xad0a004 0x4>;
		regulator-name = "cam_cc_ife_0_gdsc";
		qcom,gds-timeout = <500>;
		parent-supply = <&VDD_MM_LEVEL>;
		vdd_parent-supply = <&VDD_MM_LEVEL>;
		qcom,retain-regs;
	};

	cam_cc_ife_1_gdsc: qcom,gdsc@ad0b004 {
		compatible = "qcom,gdsc";
		reg = <0xad0b004 0x4>;
		regulator-name = "cam_cc_ife_1_gdsc";
		qcom,gds-timeout = <500>;
		parent-supply = <&VDD_MM_LEVEL>;
		vdd_parent-supply = <&VDD_MM_LEVEL>;
		qcom,retain-regs;
	};

	cam_cc_ife_2_gdsc: qcom,gdsc@ad0b070 {
		compatible = "qcom,gdsc";
		reg = <0xad0b070 0x4>;
		regulator-name = "cam_cc_ife_2_gdsc";
		qcom,gds-timeout = <500>;
		parent-supply = <&VDD_MM_LEVEL>;
		vdd_parent-supply = <&VDD_MM_LEVEL>;
		qcom,retain-regs;
	};

	cam_cc_ipe_0_gdsc: qcom,gdsc@ad08004 {
		compatible = "qcom,gdsc";
		reg = <0xad08004 0x4>;
		regulator-name = "cam_cc_ipe_0_gdsc";
		qcom,gds-timeout = <500>;
		parent-supply = <&VDD_MM_LEVEL>;
		vdd_parent-supply = <&VDD_MM_LEVEL>;
		qcom,support-hw-trigger;
		qcom,retain-regs;
	};

	cam_cc_sbi_gdsc: qcom,gdsc@ad09004 {
		compatible = "qcom,gdsc";
		reg = <0xad09004 0x4>;
		regulator-name = "cam_cc_sbi_gdsc";
		qcom,gds-timeout = <500>;
		parent-supply = <&VDD_MM_LEVEL>;
		vdd_parent-supply = <&VDD_MM_LEVEL>;
		qcom,retain-regs;
	};

	cam_cc_titan_top_gdsc: qcom,gdsc@ad0c120 {
		compatible = "qcom,gdsc";
		reg = <0xad0c120 0x4>;
		regulator-name = "cam_cc_titan_top_gdsc";
		qcom,gds-timeout = <500>;
		parent-supply = <&VDD_MM_LEVEL>;
		vdd_parent-supply = <&VDD_MM_LEVEL>;
		qcom,retain-regs;
	};

	/* DISP_CC GDSCs */
	disp_cc_mdss_core_gdsc: qcom,gdsc@af03000 {
		compatible = "qcom,gdsc";
		reg = <0xaf03000 0x4>;
		regulator-name = "disp_cc_mdss_core_gdsc";
		qcom,gds-timeout = <500>;
		parent-supply = <&VDD_MM_LEVEL>;
		vdd_parent-supply = <&VDD_MM_LEVEL>;
		qcom,support-hw-trigger;
		qcom,retain-regs;
		proxy-supply = <&disp_cc_mdss_core_gdsc>;
		qcom,proxy-consumer-enable;
	};

	gcc_apcs_gdsc_vote_ctrl: syscon@152128 {
		compatible = "syscon";
		reg = <0x152128 0x4>;
	};

	/* GCC GDSCs */
	gcc_pcie_0_gdsc: qcom,gdsc@16b004 {
		compatible = "qcom,gdsc";
		reg = <0x16b004 0x4>;
		regulator-name = "gcc_pcie_0_gdsc";
		qcom,gds-timeout = <500>;
		parent-supply = <&VDD_CX_LEVEL>;
		qcom,retain-regs;
		qcom,no-status-check-on-disable;
		qcom,collapse-vote = <&gcc_apcs_gdsc_vote_ctrl 0>;
	};

	gcc_pcie_1_gdsc: qcom,gdsc@18d004 {
		compatible = "qcom,gdsc";
		reg = <0x18d004 0x4>;
		regulator-name = "gcc_pcie_1_gdsc";
		qcom,gds-timeout = <500>;
		parent-supply = <&VDD_CX_LEVEL>;
		qcom,retain-regs;
		qcom,no-status-check-on-disable;
		qcom,collapse-vote = <&gcc_apcs_gdsc_vote_ctrl 1>;
	};

	gcc_ufs_card_gdsc: qcom,gdsc@175004 {
		compatible = "qcom,gdsc";
		reg = <0x175004 0x4>;
		regulator-name = "gcc_ufs_card_gdsc";
		qcom,gds-timeout = <500>;
		parent-supply = <&VDD_CX_LEVEL>;
		qcom,retain-regs;
	};

	gcc_ufs_phy_gdsc: qcom,gdsc@177004 {
		compatible = "qcom,gdsc";
		reg = <0x177004 0x4>;
		regulator-name = "gcc_ufs_phy_gdsc";
		qcom,gds-timeout = <500>;
		parent-supply = <&VDD_CX_LEVEL>;
		qcom,retain-regs;
	};

	gcc_usb30_prim_gdsc: qcom,gdsc@10f004 {
		compatible = "qcom,gdsc";
		reg = <0x10f004 0x4>;
		regulator-name = "gcc_usb30_prim_gdsc";
		qcom,gds-timeout = <500>;
		qcom,retain-regs;
	};

	gcc_usb30_sec_gdsc: qcom,gdsc@110004 {
		compatible = "qcom,gdsc";
		reg = <0x110004 0x4>;
		regulator-name = "gcc_usb30_sec_gdsc";
		qcom,gds-timeout = <500>;
		qcom,retain-regs;
	};

	gcc_hlos1_vote_mmnoc_mmu_tbu_hf0_gdsc: qcom,gdsc@17d050 {
		compatible = "qcom,gdsc";
		reg = <0x17d050 0x4>;
		regulator-name = "gcc_hlos1_vote_mmnoc_mmu_tbu_hf0_gdsc";
		qcom,no-status-check-on-disable;
		qcom,gds-timeout = <500>;
	};

	gcc_hlos1_vote_mmnoc_mmu_tbu_hf1_gdsc: qcom,gdsc@17d058 {
		compatible = "qcom,gdsc";
		reg = <0x17d058 0x4>;
		regulator-name = "gcc_hlos1_vote_mmnoc_mmu_tbu_hf1_gdsc";
		qcom,no-status-check-on-disable;
		qcom,gds-timeout = <500>;
	};

	gcc_hlos1_vote_mmnoc_mmu_tbu_sf0_gdsc: qcom,gdsc@17d054 {
		compatible = "qcom,gdsc";
		reg = <0x17d054 0x4>;
		regulator-name = "gcc_hlos1_vote_mmnoc_mmu_tbu_sf0_gdsc";
		qcom,no-status-check-on-disable;
		qcom,gds-timeout = <500>;
	};

	gcc_hlos1_vote_mmnoc_mmu_tbu_sf1_gdsc: qcom,gdsc@17d06c {
		compatible = "qcom,gdsc";
		reg = <0x17d06c 0x4>;
		regulator-name = "gcc_hlos1_vote_mmnoc_mmu_tbu_sf1_gdsc";
		qcom,no-status-check-on-disable;
		qcom,gds-timeout = <500>;
	};

	/* GPU_CC GDSCs */
	gpu_cc_cx_hw_ctrl: syscon@3d91540 {
		compatible = "syscon";
		reg = <0x3d91540 0x4>;
	};

	gpu_cc_cx_gdsc: qcom,gdsc@3d9106c {
		compatible = "qcom,gdsc";
		reg = <0x3d9106c 0x4>;
		regulator-name = "gpu_cc_cx_gdsc";
		hw-ctrl-addr = <&gpu_cc_cx_hw_ctrl>;
		parent-supply = <&VDD_CX_LEVEL>;
		qcom,no-status-check-on-disable;
		qcom,clk-dis-wait-val = <8>;
		qcom,gds-timeout = <500>;
		qcom,retain-regs;
	};

	gpu_cc_gx_domain_addr: syscon@3d9158c {
		compatible = "syscon";
		reg = <0x3d9158c 0x4>;
	};

	gpu_cc_gx_sw_reset: syscon@3d91008 {
		compatible = "syscon";
		reg = <0x3d91008 0x4>;
	};

	gpu_cc_gx_gdsc: qcom,gdsc@3d9100c {
		compatible = "qcom,gdsc";
		reg = <0x3d9100c 0x4>;
		regulator-name = "gpu_cc_gx_gdsc";
		qcom,gds-timeout = <500>;
		domain-addr = <&gpu_cc_gx_domain_addr>;
		sw-reset = <&gpu_cc_gx_sw_reset>;
		parent-supply = <&VDD_GFX_LEVEL>;
		vdd_parent-supply = <&VDD_GFX_LEVEL>;
		qcom,reset-aon-logic;
		qcom,retain-regs;
	};

	/* VIDEO_CC GDSCs */
	video_cc_mvs0_gdsc: qcom,gdsc@abf0d18 {
		compatible = "qcom,gdsc";
		reg = <0xabf0d18 0x4>;
		regulator-name = "video_cc_mvs0_gdsc";
		qcom,gds-timeout = <500>;
		parent-supply = <&VDD_MM_LEVEL>;
		vdd_parent-supply = <&VDD_MM_LEVEL>;
		qcom,support-hw-trigger;
		qcom,retain-regs;
	};

	video_cc_mvs0c_gdsc: qcom,gdsc@abf0bf8 {
		compatible = "qcom,gdsc";
		reg = <0xabf0bf8 0x4>;
		regulator-name = "video_cc_mvs0c_gdsc";
		qcom,gds-timeout = <500>;
		parent-supply = <&VDD_MM_LEVEL>;
		vdd_parent-supply = <&VDD_MM_LEVEL>;
		qcom,retain-regs;
	};

	video_cc_mvs1_gdsc: qcom,gdsc@abf0d98 {
		compatible = "qcom,gdsc";
		reg = <0xabf0d98 0x4>;
		regulator-name = "video_cc_mvs1_gdsc";
		qcom,gds-timeout = <500>;
		parent-supply = <&VDD_MM_LEVEL>;
		vdd_parent-supply = <&VDD_MM_LEVEL>;
		qcom,support-hw-trigger;
		qcom,retain-regs;
	};

	video_cc_mvs1c_gdsc: qcom,gdsc@abf0c98 {
		compatible = "qcom,gdsc";
		reg = <0xabf0c98 0x4>;
		regulator-name = "video_cc_mvs1c_gdsc";
		qcom,gds-timeout = <500>;
		parent-supply = <&VDD_MM_LEVEL>;
		vdd_parent-supply = <&VDD_MM_LEVEL>;
		qcom,retain-regs;
	};

	thermal_zones: thermal-zones {
	};

	qmi_tmd: qmi-tmd-devices {
		compatible = "qcom,qmi-cooling-devices";
	};

	cache-controller@9200000 {
		compatible = "qcom,lahaina-llcc";
		reg = <0x9200000 0x58000>, <0x9280000 0x58000>,
			<0x9300000 0x58000>, <0x9380000 0x58000>, <0x9600000 0x58000>;
		reg-names = "llcc0_base", "llcc1_base",
			"llcc2_base", "llcc3_base", "llcc_broadcast_base";
		interrupts = <GIC_SPI 266 IRQ_TYPE_LEVEL_HIGH>;
		cap-based-alloc-and-pwr-collapse;
	};

	qcom_scm {
		compatible = "qcom,secure-chan-manager";
	};

	qcom-secure-buffer {
		compatible = "qcom,secure-buffer";
		qcom,vmid-cp-camera-preview-ro;
	};

	qcom-mem-buf {
		compatible = "qcom,mem-buf";
		qcom,mem-buf-capabilities = "supplier";
		qcom,vmid = <3>;
	};

	qcom,mem-buf-msgq {
		compatible = "qcom,mem-buf-msgq";
		qcom,msgq-names = "trusted_vm", "oem_vm";
	};

	aggre1_noc: interconnect@16e0000 {
		compatible = "qcom,lahaina-aggre1_noc";
		reg = <0x016E0000 0x1f180>;
		#interconnect-cells = <1>;
		qcom,bcm-voter-names = "hlos";
		qcom,bcm-voters = <&apps_bcm_voter>;
		clocks = <&gcc GCC_AGGRE_UFS_PHY_AXI_CLK>,
			<&gcc GCC_AGGRE_USB3_PRIM_AXI_CLK>,
			<&gcc GCC_AGGRE_USB3_SEC_AXI_CLK>;
	};

	aggre2_noc: interconnect@1700000 {
		reg = <0x1700000 0x3d180>;
		compatible = "qcom,lahaina-aggre2_noc";
		#interconnect-cells = <1>;
		qcom,bcm-voter-names = "hlos";
		qcom,bcm-voters = <&apps_bcm_voter>;
		clocks = <&gcc GCC_AGGRE_NOC_PCIE_0_AXI_CLK>,
			<&gcc GCC_AGGRE_NOC_PCIE_1_AXI_CLK>,
			<&gcc GCC_AGGRE_UFS_CARD_AXI_CLK>,
			<&gcc GCC_AGGRE_UFS_PHY_AXI_CLK>,
			<&rpmhcc RPMH_IPA_CLK>;
	};

	clk_virt: interconnect {
		compatible = "qcom,lahaina-clk_virt";
		#interconnect-cells = <1>;
		qcom,bcm-voter-names = "hlos";
		qcom,bcm-voters = <&apps_bcm_voter>;
	};

	config_noc: interconnect@1500000 {
		reg = <0x1500000 0x28000>;
		compatible = "qcom,lahaina-config_noc";
		#interconnect-cells = <1>;
		qcom,bcm-voter-names = "hlos";
		qcom,bcm-voters = <&apps_bcm_voter>;
	};

	dc_noc: interconnect@90e0000 {
		reg = <0x90e0000 0x5080>;
		compatible = "qcom,lahaina-dc_noc";
		#interconnect-cells = <1>;
		qcom,bcm-voter-names = "hlos";
		qcom,bcm-voters = <&apps_bcm_voter>;
	};

	gem_noc: interconnect@9100000 {
		reg = <0x9100000 0xb4000>;
		compatible = "qcom,lahaina-gem_noc";
		#interconnect-cells = <1>;
		qcom,bcm-voter-names = "hlos", "disp";
		qcom,bcm-voters = <&apps_bcm_voter>, <&disp_bcm_voter>;
	};

	lpass_ag_noc: interconnect@3c40000 {
		reg = <0x03c40000 0xf080>;
		compatible = "qcom,lahaina-lpass_ag_noc";
		#interconnect-cells = <1>;
		qcom,bcm-voter-names = "hlos";
		qcom,bcm-voters = <&apps_bcm_voter>;
	};

	mc_virt: interconnect@1580000 {
		reg = <0x1580000 0x4>;
		compatible = "qcom,lahaina-mc_virt";
		#interconnect-cells = <1>;
		qcom,bcm-voter-names = "hlos", "disp";
		qcom,bcm-voters = <&apps_bcm_voter>, <&disp_bcm_voter>;
	};

	mmss_noc: interconnect@1740000 {
		reg = <0x1740000 0x1f080>;
		compatible = "qcom,lahaina-mmss_noc";
		#interconnect-cells = <1>;
		qcom,bcm-voter-names = "hlos", "disp";
		qcom,bcm-voters = <&apps_bcm_voter>, <&disp_bcm_voter>;
	};

	nsp_noc: interconnect@a0c0000 {
		reg = <0x0a0c0000 0x10000>;
		compatible = "qcom,lahaina-nsp_noc";
		#interconnect-cells = <1>;
		qcom,bcm-voter-names = "hlos";
		qcom,bcm-voters = <&apps_bcm_voter>;
	};

	system_noc: interconnect@1680000 {
		reg = <0x1680000 0x1EE00>;
		compatible = "qcom,lahaina-system_noc";
		#interconnect-cells = <1>;
		qcom,bcm-voter-names = "hlos";
		qcom,bcm-voters = <&apps_bcm_voter>;
	};

	qcom,mpm2-sleep-counter@c221000 {
		compatible = "qcom,mpm2-sleep-counter";
		reg = <0xc221000 0x1000>;
		clock-frequency = <32768>;
	};

	qcom,rmtfs_sharedmem@0 {
		compatible = "qcom,sharedmem-uio";
		reg = <0x0 0x280000>;
		reg-names = "rmtfs";
		qcom,client-id = <0x00000001>;
	};

	qcom_hwkm: hwkm@10c0000 {
		compatible = "qcom,hwkm";
		reg = <0x10c0000 0x9000>, <0x1d90000 0x9000>;
		reg-names = "km_master", "ice_slave";
		qcom,enable-hwkm-clk;

		clock-names = "km_clk_src";
		clocks = <&rpmhcc RPMH_HWKM_CLK>;
		qcom,op-freq-hz = <75000000>;
	};

	vendor_hooks: qcom,cpu-vendor-hooks {
		compatible = "qcom,cpu-vendor-hooks";
	};

	ufsphy_mem: ufsphy_mem@1d87000 {
		reg = <0x1d87000 0xe10>;
		reg-names = "phy_mem";
		#phy-cells = <0>;

		lanes-per-direction = <2>;
		clock-names = "ref_clk_src",
			"ref_aux_clk";
		clocks = <&rpmhcc RPMH_CXO_CLK>,
			<&gcc GCC_UFS_PHY_PHY_AUX_CLK>;
		resets = <&ufshc_mem 0>;
		status = "disabled";
	};

	ufshc_mem: ufshc@1d84000 {
		compatible = "qcom,ufshc";
		reg = <0x1d84000 0x3000>,
		    <0x1d88000 0x18000>;
		reg-names = "ufs_mem", "ice";
		interrupts = <GIC_SPI 265 IRQ_TYPE_LEVEL_HIGH>;
		phys = <&ufsphy_mem>;
		phy-names = "ufsphy";
		#reset-cells = <1>;
		qcom,ice-use-hwkm;

		lanes-per-direction = <2>;
		dev-ref-clk-freq = <0>; /* 19.2 MHz */
		clock-names =
			"core_clk",
			"bus_aggr_clk",
			"iface_clk",
			"core_clk_unipro",
			"core_clk_ice",
			"ref_clk",
			"tx_lane0_sync_clk",
			"rx_lane0_sync_clk",
			"rx_lane1_sync_clk";
		clocks =
			<&gcc GCC_UFS_PHY_AXI_CLK>,
			<&gcc GCC_AGGRE_UFS_PHY_AXI_CLK>,
			<&gcc GCC_UFS_PHY_AHB_CLK>,
			<&gcc GCC_UFS_PHY_UNIPRO_CORE_CLK>,
			<&gcc GCC_UFS_PHY_ICE_CORE_CLK>,
			<&rpmhcc RPMH_CXO_CLK>,
			<&gcc GCC_UFS_PHY_TX_SYMBOL_0_CLK>,
			<&gcc GCC_UFS_PHY_RX_SYMBOL_0_CLK>,
			<&gcc GCC_UFS_PHY_RX_SYMBOL_1_CLK>;
		freq-table-hz =
			<75000000 300000000>,
			<0 0>,
			<0 0>,
			<75000000 300000000>,
			<75000000 300000000>,
			<0 0>,
			<0 0>,
			<0 0>,
			<0 0>;
		interconnects = <&aggre1_noc MASTER_UFS_MEM &mc_virt SLAVE_EBI1>,
		      <&gem_noc MASTER_APPSS_PROC &config_noc SLAVE_UFS_MEM_CFG>;
		interconnect-names = "ufs-ddr", "cpu-ufs";

		reset-gpios = <&tlmm 203 GPIO_ACTIVE_LOW>;

		resets = <&gcc GCC_UFS_PHY_BCR>;
		reset-names = "rst";
		iommus = <&apps_smmu 0xE0 0x0>;
		qcom,iommu-dma = "fastmap";
		dma-coherent;

		status = "disabled";
		qos0 {
			mask = <0xf0>;
			vote = <44>;
		};


		qos1 {
			mask = <0x0f>;
			vote = <44>;
		};
	};

	sdhc_2: sdhci@8804000 {
		compatible = "qcom,sdhci-msm-v5";
		reg = <0x08804000 0x1000>;
		reg-names = "hc_mem";

		interrupts = <GIC_SPI 207 IRQ_TYPE_LEVEL_HIGH>,
				<GIC_SPI 223 IRQ_TYPE_LEVEL_HIGH>;
		interrupt-names = "hc_irq", "pwr_irq";

		qcom,bus-width = <4>;
		qcom,large-address-bus;

		interconnects = <&aggre2_noc MASTER_SDCC_2 &mc_virt SLAVE_EBI1>,
			<&gem_noc MASTER_APPSS_PROC &config_noc SLAVE_SDCC_2>;
		interconnect-names = "sdhc-ddr","cpu-sdhc";
		qcom,msm-bus,name = "sdhc2";
		qcom,msm-bus,num-cases = <8>;
		qcom,msm-bus,num-paths = <2>;
		qcom,msm-bus,vectors-KBps =
			/* No Vote */
			<0 0>, <0 0>,
			/* 400 KB/s*/
			<1046 1600>, <1600 1600>,
			/* 20 MB/s */
			<52286 80000>, <80000 80000>,
			/* 25 MB/s */
			<65360 100000>, <100000 100000>,
			/* 50 MB/s */
			<130718 200000>, <133320 133320>,
			/* 100 MB/s */
			<261438 200000>, <150000 150000>,
			/* 200 MB/s */
			<261438 400000>, <300000 300000>,
			/* Max. bandwidth */
			<1338562 4096000>, <1338562 4096000>;
		qcom,bus-bw-vectors-bps = <0 400000 20000000 25000000 50000000
			100750000 200000000 4294967295>;

		qcom,restore-after-cx-collapse;

		qcom,clk-rates = <400000 20000000 25000000
					50000000 100000000 201500000>;
		qcom,bus-speed-mode = "SDR12", "SDR25", "SDR50", "DDR50",
				      "SDR104";

		qcom,devfreq,freq-table = <50000000 201500000>;
		clocks = <&gcc GCC_SDCC2_AHB_CLK>,
			<&gcc GCC_SDCC2_APPS_CLK>;
		clock-names = "iface", "core";

		/* DLL HSR settings. Refer go/hsr - <Target> DLL settings */
		qcom,dll-hsr-list = <0x0007642C 0xA800 0x10
					0x2C010800 0x80040868>;

		qcom,scaling-lower-bus-speed-mode = "DDR52";

		iommus = <&apps_smmu 0x4a0 0x0>;
		dma-coherent;
		qcom,iommu-dma = "bypass";

		status = "disabled";

		qos0 {
			mask = <0x0f>;
			vote = <44>;
		};

		qos1 {
			mask = <0xf0>;
			vote = <44>;
		};
	};

	kryo_erp: erp {
		compatible = "arm,arm64-kryo-cpu-erp";
		interrupts = <GIC_PPI 0 IRQ_TYPE_LEVEL_HIGH>,
			<GIC_SPI 35 IRQ_TYPE_LEVEL_HIGH>;
		interrupt-names = "l1-l2-faultirq","l3-scu-faultirq";
		qcom,disable-panic-on-ce;
	};

	tcsr_mutex_block: syscon@1f40000 {
		compatible = "syscon";
		reg = <0x1f40000 0x20000>;
	};

	tcsr_mutex: hwlock {
		compatible = "qcom,tcsr-mutex";
		syscon = <&tcsr_mutex_block 0 0x1000>;
		#hwlock-cells = <1>;
	};

	tcsr: syscon@1fc0000 {
		compatible = "syscon";
		reg = <0x1fc0000 0x30000>;
	};

	smem: qcom,smem {
		compatible = "qcom,smem";
		memory-region = <&smem_mem>;
		hwlocks = <&tcsr_mutex 3>;
	};

	aoss_qmp: power-controller@c300000 {
		compatible = "qcom,aoss-qmp";
		reg = <0x0c300000 0x400>;

		interrupt-parent = <&ipcc_mproc>;
		interrupts = <IPCC_CLIENT_AOP
			      IPCC_MPROC_SIGNAL_GLINK_QMP
			      IRQ_TYPE_EDGE_RISING>;
		mboxes = <&ipcc_mproc IPCC_CLIENT_AOP
			  IPCC_MPROC_SIGNAL_GLINK_QMP>;
		#clock-cells = <0>;
		#power-domain-cells = <1>;
	};

	qmp_aop: qcom,qmp-aop@c300000 {
		compatible = "qcom,qmp-mbox";
		qcom,qmp = <&aoss_qmp>;
		label = "aop";
		qcom,early-boot;
		priority = <0>;
		mbox-desc-offset = <0x0>;
		#mbox-cells = <1>;
	};

	aop-msg-client {
		compatible = "qcom,debugfs-qmp-client";
		mboxes = <&qmp_aop 0>;
		mbox-names = "aop";
	};

	qcom,smp2p_sleepstate {
		compatible = "qcom,smp2p-sleepstate";
		qcom,smem-states = <&sleepstate_smp2p_out 0>;
		interrupt-parent = <&sleepstate_smp2p_in>;
		interrupts = <0 0>;
		interrupt-names = "smp2p-sleepstate-in";
	};

	pdc: interrupt-controller@b220000 {
		compatible = "qcom,lahaina-pdc", "qcom,pdc";
		reg = <0xb220000 0x30000>, <0x17c000f0 0x60>;
		qcom,pdc-ranges = <0 480 40>, <40 140 14>, <54 263 1>, <55 306 4>,
				  <59 312 3>, <62 374 2>, <64 434 2>, <66 438 3>,
				  <69 86 1>, <70 520 54>, <124 609 31>, <155 63 1>,
				  <156 716 12>;
		#interrupt-cells = <2>;
		interrupt-parent = <&intc>;
		interrupt-controller;
	};

	spmi_bus: qcom,spmi@c440000 {
		compatible = "qcom,spmi-pmic-arb";
		reg = <0xc440000 0x1100>,
		      <0xc600000 0x2000000>,
		      <0xe600000 0x100000>,
		      <0xe700000 0xa0000>,
		      <0xc40a000 0x26000>;
		reg-names = "core", "chnls", "obsrvr", "intr", "cnfg";
		interrupts-extended = <&pdc 1 IRQ_TYPE_LEVEL_HIGH>;
		interrupt-names = "periph_irq";
		interrupt-controller;
		#interrupt-cells = <4>;
		#address-cells = <2>;
		#size-cells = <0>;
		cell-index = <0>;
		qcom,channel = <0>;
		qcom,ee = <0>;
	};

	spmi_debug_bus: qcom,spmi-debug@6b12000 {
		compatible = "qcom,spmi-pmic-arb-debug";
		reg = <0x6b12000 0x60>, <0x7820a8 0x4>;
		reg-names = "core", "fuse";
		clocks = <&aoss_qmp>;
		clock-names = "core_clk";
		qcom,fuse-disable-bit = <24>;
		#address-cells = <2>;
		#size-cells = <0>;
		status = "disabled";

		qcom,pmk8350-debug@0 {
			compatible = "qcom,spmi-pmic";
			reg = <0 SPMI_USID>;
			#address-cells = <2>;
			#size-cells = <0>;
			qcom,can-sleep;
		};

		qcom,pm8350-debug@1 {
			compatible = "qcom,spmi-pmic";
			reg = <1 SPMI_USID>;
			#address-cells = <2>;
			#size-cells = <0>;
			qcom,can-sleep;
		};

		qcom,pm8350c-debug@2 {
			compatible = "qcom,spmi-pmic";
			reg = <2 SPMI_USID>;
			#address-cells = <2>;
			#size-cells = <0>;
			qcom,can-sleep;
		};

		qcom,pm8350b-debug@3 {
			compatible = "qcom,spmi-pmic";
			reg = <3 SPMI_USID>;
			#address-cells = <2>;
			#size-cells = <0>;
			qcom,can-sleep;
		};

		qcom,pmr735a-debug@4 {
			compatible = "qcom,spmi-pmic";
			reg = <4 SPMI_USID>;
			#address-cells = <2>;
			#size-cells = <0>;
			qcom,can-sleep;
		};

		qcom,pmr735b-debug@5 {
			compatible = "qcom,spmi-pmic";
			reg = <5 SPMI_USID>;
			#address-cells = <2>;
			#size-cells = <0>;
			qcom,can-sleep;
		};
	};

	qcom,msm-cdsp-loader {
		compatible = "qcom,cdsp-loader";
		qcom,proc-img-to-load = "cdsp";
	};

	qcom,msm-adsprpc-mem {
		compatible = "qcom,msm-adsprpc-mem-region";
		memory-region = <&adsp_mem>;
		restrict-access;
	};

	msm_fastrpc: qcom,msm_fastrpc {
		compatible = "qcom,msm-fastrpc-compute";
		qcom,adsp-remoteheap-vmid = <22 37>;
		qcom,fastrpc-adsp-audio-pdr;
		qcom,fastrpc-adsp-sensors-pdr;
		qcom,rpc-latency-us = <235>;
		qcom,fastrpc-gids = <2908>;
		qcom,qos-cores = <0 1 2 3>;

		qcom,msm_fastrpc_compute_cb1 {
			compatible = "qcom,msm-fastrpc-compute-cb";
			label = "cdsprpc-smd";
			iommus = <&apps_smmu 0x2161 0x0400>,
					 <&apps_smmu 0x1181 0x0420>;
			qcom,iommu-dma-addr-pool = <0x80000000 0x78000000>;
			qcom,iommu-faults = "stall-disable", "HUPCF";
			dma-coherent-hint-cached;
		};

		qcom,msm_fastrpc_compute_cb2 {
			compatible = "qcom,msm-fastrpc-compute-cb";
			label = "cdsprpc-smd";
			iommus = <&apps_smmu 0x2162 0x0400>,
					 <&apps_smmu 0x1182 0x0420>;
			qcom,iommu-dma-addr-pool = <0x80000000 0x78000000>;
			qcom,iommu-faults = "stall-disable", "HUPCF";
			dma-coherent-hint-cached;
		};

		qcom,msm_fastrpc_compute_cb3 {
			compatible = "qcom,msm-fastrpc-compute-cb";
			label = "cdsprpc-smd";
			iommus = <&apps_smmu 0x2163 0x0400>,
					 <&apps_smmu 0x1183 0x0420>;
			qcom,iommu-dma-addr-pool = <0x80000000 0x78000000>;
			qcom,iommu-faults = "stall-disable", "HUPCF";
			dma-coherent-hint-cached;
		};

		qcom,msm_fastrpc_compute_cb4 {
			compatible = "qcom,msm-fastrpc-compute-cb";
			label = "cdsprpc-smd";
			iommus = <&apps_smmu 0x2164 0x0400>,
					 <&apps_smmu 0x1184 0x0420>;
			qcom,iommu-dma-addr-pool = <0x80000000 0x78000000>;
			qcom,iommu-faults = "stall-disable", "HUPCF";
			dma-coherent-hint-cached;
		};

		qcom,msm_fastrpc_compute_cb5 {
			compatible = "qcom,msm-fastrpc-compute-cb";
			label = "cdsprpc-smd";
			iommus = <&apps_smmu 0x2165 0x0400>,
					 <&apps_smmu 0x1185 0x0420>;
			qcom,iommu-dma-addr-pool = <0x80000000 0x78000000>;
			qcom,iommu-faults = "stall-disable", "HUPCF";
			dma-coherent-hint-cached;
		};

		qcom,msm_fastrpc_compute_cb6 {
			compatible = "qcom,msm-fastrpc-compute-cb";
			label = "cdsprpc-smd";
			iommus = <&apps_smmu 0x2166 0x0400>,
					 <&apps_smmu 0x1186 0x0420>;
			qcom,iommu-dma-addr-pool = <0x80000000 0x78000000>;
			qcom,iommu-faults = "stall-disable", "HUPCF";
			dma-coherent-hint-cached;
		};

		qcom,msm_fastrpc_compute_cb7 {
			compatible = "qcom,msm-fastrpc-compute-cb";
			label = "cdsprpc-smd";
			iommus = <&apps_smmu 0x2167 0x0400>,
					 <&apps_smmu 0x1187 0x0420>;
			qcom,iommu-dma-addr-pool = <0x80000000 0x78000000>;
			qcom,iommu-faults = "stall-disable", "HUPCF";
			dma-coherent-hint-cached;
		};

		qcom,msm_fastrpc_compute_cb8 {
			compatible = "qcom,msm-fastrpc-compute-cb";
			label = "cdsprpc-smd";
			iommus = <&apps_smmu 0x2168 0x0400>,
					 <&apps_smmu 0x1188 0x0420>;
			qcom,iommu-dma-addr-pool = <0x80000000 0x78000000>;
			qcom,iommu-faults = "stall-disable", "HUPCF";
			dma-coherent-hint-cached;
		};

		qcom,msm_fastrpc_compute_cb9 {
			compatible = "qcom,msm-fastrpc-compute-cb";
			label = "cdsprpc-smd";
			qcom,secure-context-bank;
			iommus = <&apps_smmu 0x2169 0x0400>,
					 <&apps_smmu 0x1189 0x0420>;
			qcom,iommu-dma-addr-pool = <0x60000000 0x78000000>;
			qcom,iommu-faults = "stall-disable", "HUPCF";
			qcom,iommu-vmid = <0xA>;	/* VMID_CP_PIXEL */
			dma-coherent-hint-cached;
		};

		qcom,msm_fastrpc_compute_cb10 {
			compatible = "qcom,msm-fastrpc-compute-cb";
			label = "adsprpc-smd";
			iommus = <&apps_smmu 0x1803 0x0>;
			qcom,iommu-dma-addr-pool = <0x80000000 0x78000000>;
			qcom,iommu-faults = "stall-disable", "HUPCF";
			dma-coherent-hint-cached;
		};

		qcom,msm_fastrpc_compute_cb11 {
			compatible = "qcom,msm-fastrpc-compute-cb";
			label = "adsprpc-smd";
			iommus = <&apps_smmu 0x1804 0x0>;
			qcom,iommu-dma-addr-pool = <0x80000000 0x78000000>;
			qcom,iommu-faults = "stall-disable", "HUPCF";
			dma-coherent-hint-cached;
		};

		qcom,msm_fastrpc_compute_cb12 {
			compatible = "qcom,msm-fastrpc-compute-cb";
			label = "adsprpc-smd";
			iommus = <&apps_smmu 0x1805 0x0>;
			qcom,iommu-dma-addr-pool = <0x80000000 0x78000000>;
			qcom,iommu-faults = "stall-disable", "HUPCF";
			dma-coherent-hint-cached;
		};

		qcom,msm_fastrpc_compute_cb13 {
			compatible = "qcom,msm-fastrpc-compute-cb";
			label = "sdsprpc-smd";
			iommus = <&apps_smmu 0x0541 0x0>;
			qcom,iommu-dma-addr-pool = <0x80000000 0x78000000>;
			qcom,iommu-faults = "stall-disable", "HUPCF";
			dma-coherent-hint-cached;
		};

		qcom,msm_fastrpc_compute_cb14 {
			compatible = "qcom,msm-fastrpc-compute-cb";
			label = "sdsprpc-smd";
			iommus = <&apps_smmu 0x0542 0x0>;
			qcom,iommu-dma-addr-pool = <0x80000000 0x78000000>;
			qcom,iommu-faults = "stall-disable", "HUPCF";
			dma-coherent-hint-cached;
		};

		qcom,msm_fastrpc_compute_cb15 {
			compatible = "qcom,msm-fastrpc-compute-cb";
			label = "sdsprpc-smd";
			iommus = <&apps_smmu 0x0543 0x0>;
			qcom,iommu-dma-addr-pool = <0x80000000 0x78000000>;
			qcom,iommu-faults = "stall-disable", "HUPCF";
			shared-cb = <4>;
			dma-coherent-hint-cached;
		};

		qcom,msm_fastrpc_compute_cb16 {
			compatible = "qcom,msm-fastrpc-compute-cb";
			label = "cdsprpc-smd";
			iommus = <&apps_smmu 0x118B 0x0420>,
					 <&apps_smmu 0x216B 0x0400>;
			qcom,iommu-dma-addr-pool = <0x80000000 0x78000000>;
			qcom,iommu-faults = "stall-disable", "HUPCF";
			dma-coherent-hint-cached;
		};

		qcom,msm_fastrpc_compute_cb17 {
			compatible = "qcom,msm-fastrpc-compute-cb";
			label = "cdsprpc-smd";
			iommus = <&apps_smmu 0x118C 0x0420>,
					 <&apps_smmu 0x216C 0x0400>;
			qcom,iommu-dma-addr-pool = <0x80000000 0x78000000>;
			qcom,iommu-faults = "stall-disable", "HUPCF";
			dma-coherent-hint-cached;
		};

		qcom,msm_fastrpc_compute_cb18 {
			compatible = "qcom,msm-fastrpc-compute-cb";
			label = "cdsprpc-smd";
			iommus = <&apps_smmu 0x118D 0x0420>,
					 <&apps_smmu 0x216D 0x0400>;
			qcom,iommu-dma-addr-pool = <0x80000000 0x78000000>;
			qcom,iommu-faults = "stall-disable", "HUPCF";
			dma-coherent-hint-cached;
		};

		qcom,msm_fastrpc_compute_cb19 {
			compatible = "qcom,msm-fastrpc-compute-cb";
			label = "cdsprpc-smd";
			iommus = <&apps_smmu 0x118E 0x0420>,
					 <&apps_smmu 0x216E 0x0400>;
			qcom,iommu-dma-addr-pool = <0x80000000 0x78000000>;
			qcom,iommu-faults = "stall-disable", "HUPCF";
			dma-coherent-hint-cached;
		};
	};

	llcc_pmu: llcc-pmu@9095000 {
		compatible = "qcom,llcc-pmu-ver2";
		reg = <0x09095000 0x300>;
		reg-names = "lagg-base";
	};

	qcom_pmu: qcom,pmu {
		compatible = "qcom,pmu";
		qcom,pmu-events-tbl =
			< 0x0008 0xFF 0xFF 0xFF >,
			< 0x0011 0xFF 0xFF 0xFF >,
			< 0x0017 0xFF 0xFF 0xFF >,
			< 0x002A 0xFF 0xFF 0xFF >,
			< 0x1000 0xFF 0xFF 0xFF >;
	};

	llcc_freq_table: llcc-freq-table {
		qcom,freq-tbl =
			<  150000 >,
			<  300000 >,
			<  466000 >,
			<  600000 >,
			<  806000 >,
			<  933000 >,
			< 1000000 >;
	};

	ddr_freq_table: ddr-freq-table {
		ddr4 {
			qcom,ddr-type = <7>;
			qcom,freq-tbl =
				<  200000 >,
				<  451000 >,
				<  547000 >,
				<  681000 >,
				<  768000 >,
				< 1017000 >,
				< 1353000 >,
				< 1555000 >,
				< 1708000 >,
				< 2092000 >,
				< 2133000 >,
				< 2736000 >,
				< 3196000 >;
		};

		ddr5 {
			qcom,ddr-type = <8>;
			qcom,freq-tbl =
				<  200000 >,
				<  451000 >,
				<  547000 >,
				<  681000 >,
				<  768000 >,
				< 1017000 >,
				< 1353000 >,
				< 1555000 >,
				< 1708000 >,
				< 2092000 >,
				< 2133000 >,
				< 2736000 >,
				< 3196000 >;
		};
	};

	ddrqos_freq_table: ddrqos-freq-table {
		qcom,freq-tbl =
			< 0 >,
			< 1 >;
	};

	qcom_dcvs: qcom,dcvs {
		compatible = "qcom,dcvs";
		#address-cells = <1>;
		#size-cells = <1>;
		ranges;

		qcom_ddr_dcvs_hw: ddr {
			compatible = "qcom,dcvs-hw";
			qcom,dcvs-hw-type = <0>;
			qcom,bus-width = <4>;
			qcom,freq-tbl = <&ddr_freq_table>;

			ddr_dcvs_sp: sp {
				compatible = "qcom,dcvs-path";
				qcom,dcvs-path-type = <0>;
				interconnects = <&mc_virt MASTER_LLCC
						 &mc_virt SLAVE_EBI1>;
			};
		};

		qcom_llcc_dcvs_hw: llcc {
			compatible = "qcom,dcvs-hw";
			qcom,dcvs-hw-type = <1>;
			qcom,bus-width = <16>;
			qcom,freq-tbl = <&llcc_freq_table>;

			llcc_dcvs_sp: sp {
				compatible = "qcom,dcvs-path";
				qcom,dcvs-path-type = <0>;
				interconnects = <&gem_noc MASTER_APPSS_PROC
						 &gem_noc SLAVE_LLCC>;
			};
		};

		qcom_l3_dcvs_hw: l3 {
			compatible = "qcom,dcvs-hw";
			qcom,dcvs-hw-type = <2>;
			qcom,bus-width = <32>;
			reg = <0x18590000 0x4000>, <0x18590100 0xa0>;
			reg-names = "l3-base", "l3tbl-base";

			l3_dcvs_sp: sp {
				compatible = "qcom,dcvs-path";
				qcom,dcvs-path-type = <0>;
				qcom,shared-offset = <0x0920>;
			};
		};

		qcom_ddrqos_dcvs_hw: ddrqos {
			compatible = "qcom,dcvs-hw";
			qcom,dcvs-hw-type = <3>;
			qcom,bus-width = <1>;
			qcom,freq-tbl = <&ddrqos_freq_table>;

			ddrqos_dcvs_sp: sp {
				compatible = "qcom,dcvs-path";
				qcom,dcvs-path-type = <0>;
				interconnects = <&mc_virt MASTER_LLCC
						&mc_virt SLAVE_EBI1>;
			};
		};

	};

	qcom_memlat: qcom,memlat {
		compatible = "qcom,memlat";
		ddr {
			compatible = "qcom,memlat-grp";
			qcom,target-dev = <&qcom_ddr_dcvs_hw>;
			qcom,sampling-path = <&ddr_dcvs_sp>;
			qcom,miss-ev = <0x1000>;

			silver {
				compatible = "qcom,memlat-mon";
				qcom,cpulist = <&CPU0 &CPU1 &CPU2 &CPU3>;
				qcom,sampling-enabled;

				ddr4-tbl {
					qcom,ddr-type = <7>;
					qcom,cpufreq-memfreq-tbl =
						<  300000  200000 >,
						<  691200  451000 >,
						< 1190400  547000 >,
						< 1459200  768000 >,
						< 1900800 1017000 >;
				};

				ddr5-tbl {
					qcom,ddr-type = <8>;
					qcom,cpufreq-memfreq-tbl =
					<  300000  200000 >,
					<  691200  451000 >,
					< 1190400  547000 >,
					< 1459200  768000 >,
					< 1900800 1555000 >;
				};
			};

			gold {
				compatible = "qcom,memlat-mon";
				qcom,cpulist = <&CPU4 &CPU5 &CPU6>;
				qcom,sampling-enabled;
				ddr4-tbl {
					qcom,ddr-type = <7>;
					qcom,cpufreq-memfreq-tbl =
						<  300000  200000 >,
						<  672000  451000 >,
						<  902400  547000 >,
						< 1017600  768000 >,
						< 1305600 1017000 >,
						< 1593600 1353000 >,
						< 1804800 1555000 >,
						< 2188800 1708000 >,
						< 2400000 2133000 >;
				};

				ddr5-tbl {
					qcom,ddr-type = <8>;
					qcom,cpufreq-memfreq-tbl =
						<  300000  200000 >,
						<  672000  451000 >,
						<  902400  547000 >,
						< 1017600  768000 >,
						< 1804800 1555000 >,
						< 2304000 2092000 >,
						< 2400000 3196000 >;
				};
			};

			prime {
				compatible = "qcom,memlat-mon";
				qcom,cpulist = <&CPU7>;
				qcom,sampling-enabled;
				ddr4-tbl {
					qcom,ddr-type = <7>;
					qcom,cpufreq-memfreq-tbl =
					< 2304000  200000 >,
					< 2400000 2133000 >;
				};

				ddr5-tbl {
					qcom,ddr-type = <8>;
					qcom,cpufreq-memfreq-tbl =
					< 2304000   200000 >,
					< 2400000  3196000 >;
				};
			};

			gold-compute {
				compatible = "qcom,memlat-mon";
				qcom,cpulist = <&CPU4 &CPU5 &CPU6>;
				qcom,sampling-enabled;
				qcom,compute-mon;
				ddr4-tbl {
					qcom,ddr-type = <7>;
					qcom,cpufreq-memfreq-tbl =
					< 1804800  200000 >,
					< 2400000 1017000 >;
				};

				ddr5-tbl {
					qcom,ddr-type = <8>;
					qcom,cpufreq-memfreq-tbl =
					< 1804800  200000 >,
					< 2400000 1555000 >;
				};
			};

		};

		llcc {
			compatible = "qcom,memlat-grp";
			qcom,target-dev = <&qcom_llcc_dcvs_hw>;
			qcom,sampling-path = <&llcc_dcvs_sp>;
			qcom,miss-ev = <0x2A>;

			silver {
				compatible = "qcom,memlat-mon";
				qcom,cpulist = <&CPU0 &CPU1 &CPU2 &CPU3>;
				qcom,sampling-enabled;
				qcom,cpufreq-memfreq-tbl =
				<  300000 150000 >,
				<  691200 300000 >,
				< 1459200 466000 >,
				< 1900800 600000 >;
			};

			gold {
				compatible = "qcom,memlat-mon";
				qcom,cpulist = <&CPU4 &CPU5 &CPU6>;
				qcom,sampling-enabled;
				qcom,cpufreq-memfreq-tbl =
				<  300000  150000 >,
				<  672000  300000 >,
				< 1017600  466000 >,
				< 1305600  600000 >,
				< 1804800  806000 >,
				< 2304000  933000 >,
				< 2400000 1000000 >;
			};

			gold-compute {
				compatible = "qcom,memlat-mon";
				qcom,cpulist = <&CPU4 &CPU5 &CPU6 &CPU7>;
				qcom,sampling-enabled;
				qcom,compute-mon;
				qcom,cpufreq-memfreq-tbl =
				< 1804800  150000 >,
				< 2400000  600000 >;
			};

		};

		l3 {
			compatible = "qcom,memlat-grp";
			qcom,target-dev = <&qcom_l3_dcvs_hw>;
			qcom,sampling-path = <&l3_dcvs_sp>;
			qcom,miss-ev = <0x17>;

			silver {
				compatible = "qcom,memlat-mon";
				qcom,cpulist = <&CPU0 &CPU1 &CPU2 &CPU3>;
				qcom,sampling-enabled;
				qcom,cpufreq-memfreq-tbl =
					<  300000  300000 >,
					<  403200  403200 >,
					<  499200  499200 >,
					<  691200  614400 >,
					<  806400  710400 >,
					<  998400  806400 >,
					< 1190400  998400 >,
					< 1286400 1094400 >,
					< 1459200 1248000 >,
					< 1728000 1344000 >,
					< 1804800 1440000 >,
					< 1900800 1516800 >;
			};

			gold {
				compatible = "qcom,memlat-mon";
				qcom,cpulist = <&CPU4 &CPU5 &CPU6>;
				qcom,sampling-enabled;
				qcom,cpufreq-memfreq-tbl =
					<  300000  300000 >,
					<  787200  614400 >,
					< 1209600  806400 >,
					< 1497600  998400 >,
					< 1689600 1248000 >,
					< 1900800 1344000 >,
					< 2188800 1440000 >,
					< 2400000 1516800 >;
			};

			prime {
				compatible = "qcom,memlat-mon";
				qcom,cpulist = <&CPU7>;
				qcom,sampling-enabled;
				qcom,cpufreq-memfreq-tbl =
					<  300000  300000 >,
					<  787200  614400 >,
					< 1209600  806400 >,
					< 1497600  998400 >,
					< 1689600 1248000 >,
					< 1900800 1344000 >,
					< 2188800 1440000 >,
					< 2400000 1516800 >;
			};

			prime-compute {
				compatible = "qcom,memlat-mon";
				qcom,cpulist = <&CPU7>;
				qcom,sampling-enabled;
				qcom,compute-mon;
				qcom,cpufreq-memfreq-tbl =
					< 1996800  300000 >,
					< 2400000  1516800 >;
			};
		};

		ddrqos {
			compatible = "qcom,memlat-grp";
			qcom,target-dev = <&qcom_ddrqos_dcvs_hw>;
			qcom,sampling-path = <&ddrqos_dcvs_sp>;
			qcom,miss-ev = <0x1000>;

			gold {
				compatible = "qcom,memlat-mon";
				qcom,cpulist = <&CPU4 &CPU5 &CPU6>;
				qcom,sampling-enabled;
				qcom,cpufreq-memfreq-tbl =
					< 300000  0 >,
					< 3000000 1 >;
			};

			prime {
				compatible = "qcom,memlat-mon";
				qcom,cpulist = <&CPU7>;
				qcom,sampling-enabled;
				qcom,cpufreq-memfreq-tbl =
					< 1996800 0 >,
					< 2400000 1 >;
			};
		};
	};

	bwmon_llcc: qcom,bwmon-llcc@90b6400 {
		compatible = "qcom,bwmon4";
		reg = <0x90b6400 0x300>, <0x90b6300 0x200>;
		reg-names = "base", "global_base";
		interrupts = <GIC_SPI 581 IRQ_TYPE_LEVEL_HIGH>;
		qcom,mport = <0>;
		qcom,hw-timer-hz = <19200000>;
		qcom,target-dev = <&qcom_llcc_dcvs_hw>;
		qcom,count-unit = <0x10000>;
	};

	bwmon_ddr: qcom,bwmon-ddr@9091000 {
		compatible = "qcom,bwmon5";
		reg = <0x9091000 0x1000>;
		reg-names = "base";
		interrupts = <GIC_SPI 81 IRQ_TYPE_LEVEL_HIGH>;
		qcom,hw-timer-hz = <19200000>;
		qcom,target-dev = <&qcom_ddr_dcvs_hw>;
		qcom,count-unit = <0x10000>;
	};

	wdog: qcom,wdt@17c10000 {
		compatible = "qcom,msm-watchdog";
		reg = <0x17c10000 0x1000>;
		reg-names = "wdt-base";
		interrupts = <0 0 IRQ_TYPE_LEVEL_HIGH>;
	};

	tsens0: tsens@c222000 {
		compatible = "qcom,tsens-v2";
		reg = <0x0C263000 0x1ff>,
			<0x0C222000 0x8>;
		#qcom,sensors = <15>;
		interrupts = <GIC_SPI 506 IRQ_TYPE_LEVEL_HIGH>,
				<GIC_SPI 508 IRQ_TYPE_LEVEL_HIGH>;
		interrupt-names = "uplow","critical";
		#thermal-sensor-cells = <1>;
	};

	tsens1: tsens@c223000 {
		compatible = "qcom,tsens-v2";
		reg = <0x0C265000 0x1ff>,
			<0x0C223000 0x8>;
		#qcom,sensors = <14>;
		interrupts = <GIC_SPI 507 IRQ_TYPE_LEVEL_HIGH>,
				<GIC_SPI 509 IRQ_TYPE_LEVEL_HIGH>;
		interrupt-names = "uplow","critical";
		#thermal-sensor-cells = <1>;
	};

	msm_gpu: qcom,kgsl-3d0@3d00000 {
	};


	qcom,glink {
		compatible = "qcom,glink";

		glink_spss: spss {
			qcom,remote-pid = <8>;
			transport = "spss";
			mboxes = <&ipcc_mproc IPCC_CLIENT_SPSS
				  IPCC_MPROC_SIGNAL_GLINK_QMP>;
			mbox-names = "spss_spss";
			interrupt-parent = <&ipcc_mproc>;
			interrupts = <IPCC_CLIENT_SPSS
				      IPCC_MPROC_SIGNAL_GLINK_QMP
				      IRQ_TYPE_LEVEL_HIGH>;

			reg = <0x1885008 0x8>,
			      <0x1885010 0x4>;
			reg-names = "qcom,spss-addr",
				    "qcom,spss-size";

			label = "spss";
			qcom,glink-label = "spss";

			qcom,spss_glink_ssr {
				qcom,glink-channels = "glink_ssr";
			};
		};
	};

	qcom,glinkpkt {
		compatible = "qcom,glinkpkt";

		qcom,glinkpkt-at-mdm0 {
			qcom,glinkpkt-edge = "mpss";
			qcom,glinkpkt-ch-name = "DS";
			qcom,glinkpkt-dev-name = "at_mdm0";
		};

		qcom,glinkpkt-apr-apps2 {
			qcom,glinkpkt-edge = "adsp";
			qcom,glinkpkt-ch-name = "apr_apps2";
			qcom,glinkpkt-dev-name = "apr_apps2";
		};

		qcom,glinkpkt-data40-cntl {
			qcom,glinkpkt-edge = "mpss";
			qcom,glinkpkt-ch-name = "DATA40_CNTL";
			qcom,glinkpkt-dev-name = "smdcntl8";
		};

		qcom,glinkpkt-data1 {
			qcom,glinkpkt-edge = "mpss";
			qcom,glinkpkt-ch-name = "DATA1";
			qcom,glinkpkt-dev-name = "smd7";
		};

		qcom,glinkpkt-data4 {
			qcom,glinkpkt-edge = "mpss";
			qcom,glinkpkt-ch-name = "DATA4";
			qcom,glinkpkt-dev-name = "smd8";
		};

		qcom,glinkpkt-data11 {
			qcom,glinkpkt-edge = "mpss";
			qcom,glinkpkt-ch-name = "DATA11";
			qcom,glinkpkt-dev-name = "smd11";
		};
	};

	modem_pas: remoteproc-mss@8a800000 {
		compatible = "qcom,lahaina-modem-pas";
		reg = <0x4080000 0x100>;

		clocks = <&rpmhcc RPMH_CXO_CLK>;
		clock-names = "xo";

		cx-supply = <&VDD_CX_LEVEL>;
		cx-uV-uA = <RPMH_REGULATOR_LEVEL_TURBO 100000>;
		mx-supply = <&VDD_MODEM_LEVEL>;
		mx-uV-uA = <RPMH_REGULATOR_LEVEL_TURBO 100000>;
		reg-names = "cx", "mx";

		interconnects = <&mc_virt MASTER_LLCC &mc_virt SLAVE_EBI1>,
				<&aggre2_noc MASTER_CRYPTO &mc_virt SLAVE_EBI1>;
		interconnect-names = "rproc_ddr", "crypto_ddr";

		memory-region = <&pil_modem_mem>;
		firmware-name = "modem.mdt";

		qcom,aux-minidump-ids = <4>;

		qcom,qmp = <&aoss_qmp>;

		/* Inputs from mss */
		interrupts-extended = <&intc GIC_SPI 264 IRQ_TYPE_EDGE_RISING>,
				<&modem_smp2p_in 0 0>,
				<&modem_smp2p_in 2 0>,
				<&modem_smp2p_in 1 0>,
				<&modem_smp2p_in 3 0>,
				<&modem_smp2p_in 7 0>;

		interrupt-names = "wdog",
				"fatal",
				"handover",
				"ready",
				"stop-ack",
				"shutdown-ack";

		/* Outputs to mss */
		qcom,smem-states = <&modem_smp2p_out 0>;
		qcom,smem-state-names = "stop";

		glink-edge {
			qcom,remote-pid = <1>;
			transport = "smem";
			mboxes = <&ipcc_mproc IPCC_CLIENT_MPSS
				  IPCC_MPROC_SIGNAL_GLINK_QMP>;
			mbox-names = "mpss_smem";
			interrupt-parent = <&ipcc_mproc>;
			interrupts = <IPCC_CLIENT_MPSS
				      IPCC_MPROC_SIGNAL_GLINK_QMP
				      IRQ_TYPE_EDGE_RISING>;

			label = "modem";
			qcom,glink-label = "mpss";

			qcom,modem_qrtr {
				qcom,glink-channels = "IPCRTR";
				qcom,low-latency;
				qcom,intents = <0x800  5
						0x2000 3
						0x4400 2>;
			};

			qcom,modem_ds {
				qcom,glink-channels = "DS";
				qcom,intents = <0x4000 0x2>;
			};

		};
	};

	adsp_pas: remoteproc-adsp@17300000 {
		compatible = "qcom,lahaina-adsp-pas";
		reg = <0x17300000 0x00100>;

		cx-supply = <&VDD_LPI_CX_LEVEL>;
		cx-uV-uA = <RPMH_REGULATOR_LEVEL_TURBO 0>;
		mx-supply = <&VDD_LPI_MX_LEVEL>;
		mx-uV-uA = <RPMH_REGULATOR_LEVEL_TURBO 0>;
		reg-names = "cx","mx";

		clocks = <&rpmhcc RPMH_CXO_CLK>;
		clock-names = "xo";

		firmware-name = "adsp.mdt";
		memory-region = <&pil_adsp_mem>;

		qcom,qmp = <&aoss_qmp>;

		/* Inputs from lpass */
		interrupts-extended = <&pdc 6 IRQ_TYPE_EDGE_RISING>,
				<&adsp_smp2p_in 0 0>,
				<&adsp_smp2p_in 2 0>,
				<&adsp_smp2p_in 1 0>,
				<&adsp_smp2p_in 3 0>;

		interrupt-names = "wdog",
				"fatal",
				"handover",
				"ready",
				"stop-ack";

		/* Outputs to lpass */
		qcom,smem-states = <&adsp_smp2p_out 0>;
		qcom,smem-state-names = "stop";

		remoteproc_adsp_glink: glink-edge {
			qcom,remote-pid = <2>;
			transport = "smem";
			mboxes = <&ipcc_mproc IPCC_CLIENT_LPASS
				  IPCC_MPROC_SIGNAL_GLINK_QMP>;
			mbox-names = "adsp_smem";
			interrupt-parent = <&ipcc_mproc>;
			interrupts = <IPCC_CLIENT_LPASS
					  IPCC_MPROC_SIGNAL_GLINK_QMP
					  IRQ_TYPE_EDGE_RISING>;

			label = "adsp";
			qcom,glink-label = "lpass";

			qcom,adsp_qrtr {
				qcom,glink-channels = "IPCRTR";
				qcom,intents = <0x800  5
						0x2000 3
						0x4400 2>;
			};

			qcom,pmic_glink_rpmsg {
				qcom,glink-channels = "PMIC_RTR_ADSP_APPS";
			};

			qcom,pmic_glink_log_rpmsg {
				qcom,glink-channels = "PMIC_LOGS_ADSP_APPS";
				qcom,intents = <0x800 5
						0xc00 3>;
			};
		};

	};

	cdsp_pas: remoteproc-cdsp@0x98900000 {
		compatible = "qcom,lahaina-cdsp-pas";
		reg = <0x98900000 0x1400000>;

		cx-supply = <&VDD_CX_LEVEL>;
		cx-uV-uA = <RPMH_REGULATOR_LEVEL_TURBO 100000>;
		mx-supply = <&VDD_MXC_LEVEL>;
		mx-uV-uA = <RPMH_REGULATOR_LEVEL_TURBO 100000>;
		reg-names = "cx","mx";

		clocks = <&rpmhcc RPMH_CXO_CLK>;
		clock-names = "xo";
		qcom,proxy-clock-names = "xo";

		firmware-name = "cdsp.mdt";
		memory-region = <&pil_cdsp_mem>;

		qcom,qmp = <&aoss_qmp>;

		interconnects = <&nsp_noc MASTER_CDSP_PROC &mc_virt SLAVE_EBI1>,
				<&aggre2_noc MASTER_CRYPTO &mc_virt SLAVE_EBI1>;
		interconnect-names = "rproc_ddr", "crypto_ddr";

		/* Inputs from turing */
		interrupts-extended = <&intc GIC_SPI 578 IRQ_TYPE_EDGE_RISING>,
				<&cdsp_smp2p_in 0 0>,
				<&cdsp_smp2p_in 2 0>,
				<&cdsp_smp2p_in 1 0>,
				<&cdsp_smp2p_in 3 0>;

		interrupt-names = "wdog",
				"fatal",
				"handover",
				"ready",
				"stop-ack";

		/* Outputs to turing */
		qcom,smem-states = <&cdsp_smp2p_out 0>;
		qcom,smem-state-names = "stop";

		remoteproc_cdsp_glink: glink-edge {
			qcom,remote-pid = <5>;
			transport = "smem";
			mboxes = <&ipcc_mproc IPCC_CLIENT_CDSP
				  IPCC_MPROC_SIGNAL_GLINK_QMP>;
			mbox-names = "dsps_smem";
			interrupt-parent = <&ipcc_mproc>;
			interrupts = <IPCC_CLIENT_CDSP
					  IPCC_MPROC_SIGNAL_GLINK_QMP
					  IRQ_TYPE_EDGE_RISING>;

			label = "cdsp";
			qcom,glink-label = "cdsp";

			qcom,cdsp_qrtr {
				qcom,glink-channels = "IPCRTR";
				qcom,intents = <0x800  5
						0x2000 3
						0x4400 2>;
			};

			qcom,msm_cdsprm_rpmsg {
				compatible = "qcom,msm-cdsprm-rpmsg";
				qcom,glink-channels = "cdsprmglink-apps-dsp";
				qcom,intents = <0x20 12>;

				msm_cdsp_rm: qcom,msm_cdsp_rm {
					compatible = "qcom,msm-cdsp-rm";
					qcom,qos-latency-us = <70>;
					qcom,qos-maxhold-ms = <20>;
				};
			};
		};

	};

	qcom,sps {
		compatible = "qcom,msm-sps-v1_7-4k";
		qcom,pipe-attr-ee;
	};

	qcom,evass@abb0000 {
		reg = <0xabb0000 0x2000>;
		status = "ok";
		qcom,pas-id = <26>;
		qcom,firmware-name = "evass";

		memory-region = <&pil_cvp_mem>;
	};

	slpi_pas: remoteproc-slpi@5c00000 {
		compatible = "qcom,lahaina-slpi-pas";
		reg = <0x5c00000 0x4000>;

		cx-supply = <&VDD_LPI_CX_LEVEL>;
		cx-uV-uA = <RPMH_REGULATOR_LEVEL_TURBO 0>;
		mx-supply = <&VDD_LPI_MX_LEVEL>;
		mx-uV-uA = <RPMH_REGULATOR_LEVEL_TURBO 0>;
		reg-names = "cx", "mx";

		clocks = <&rpmhcc RPMH_CXO_CLK>;
		clock-names = "xo";
		qcom,proxy-clock-names = "xo";

		firmware-name = "slpi.mdt";
		status = "ok";
		memory-region = <&pil_slpi_mem>;
		qcom,qmp = <&aoss_qmp>;

		/* Inputs from ssc */
		interrupts-extended = <&pdc 9 IRQ_TYPE_EDGE_RISING>,
				<&dsps_smp2p_in 0 0>,
				<&dsps_smp2p_in 2 0>,
				<&dsps_smp2p_in 1 0>,
				<&dsps_smp2p_in 3 0>;

		interrupt-names = "wdog",
				"fatal",
				"handover",
				"ready",
				"stop-ack";

		/* Outputs to ssc */
		qcom,smem-states = <&dsps_smp2p_out 0>;
		qcom,smem-state-names = "stop";

		remoteproc_slpi_glink: glink-edge {
			qcom,remote-pid = <3>;
			transport = "smem";
			mboxes = <&ipcc_mproc IPCC_CLIENT_SLPI
				  IPCC_MPROC_SIGNAL_GLINK_QMP>;
			mbox-names = "dsps_smem";
			interrupt-parent = <&ipcc_mproc>;
			interrupts = <IPCC_CLIENT_SLPI
				      IPCC_MPROC_SIGNAL_GLINK_QMP
				      IRQ_TYPE_EDGE_RISING>;

			label = "slpi";
			qcom,glink-label = "dsps";

			qcom,slpi_qrtr {
				qcom,glink-channels = "IPCRTR";
				qcom,net-id = <2>;
				qcom,low-latency;
				qcom,intents = <0x800  5
						0x2000 3
						0x4400 2>;
			};
		};
	};

	/* PIL spss node - for loading Secure Processor */
	spss_pas: remoteproc-spss@1880000 {
		compatible = "qcom,lahaina-spss-pas";
		ranges;
		reg = <0x188101c 0x4>,
		      <0x1881024 0x4>,
		      <0x1881028 0x4>,
		      <0x188103c 0x4>,
		      <0x1881100 0x4>,
		      <0x1882014 0x4>;
		reg-names = "sp2soc_irq_status", "sp2soc_irq_clr",
			    "sp2soc_irq_mask", "rmb_err",
			    "rmb_general_purpose", "rmb_err_spare2";
		interrupts = <0 352 1>;

		#address-cells = <1>;
		#size-cells = <1>;

		cx-supply = <&VDD_CX_LEVEL>;
		qcom,proxy-reg-names = "cx";
		cx-uV-uA = <RPMH_REGULATOR_LEVEL_TURBO 100000>;
		mx-supply = <&VDD_MXA_LEVEL>;
		mx-uV = <RPMH_REGULATOR_LEVEL_TURBO 100000>;

		clocks = <&rpmhcc RPMH_CXO_CLK>;
		clock-names = "xo";
		qcom,proxy-clock-names = "xo";
		status = "ok";

		qcom,qmp = <&aoss_qmp>;

		memory-region = <&pil_spss_mem>;
		qcom,spss-scsr-bits = <24 25>;
		qcom,extra-size = <4096>;

		glink-edge {
			qcom,remote-pid = <8>;
			transport = "spss";
			mboxes = <&ipcc_mproc IPCC_CLIENT_SPSS
				IPCC_MPROC_SIGNAL_GLINK_QMP>;
			mbox-names = "spss_spss";
			interrupt-parent = <&ipcc_mproc>;
			interrupts = <IPCC_CLIENT_SPSS
				     IPCC_MPROC_SIGNAL_GLINK_QMP
				     IRQ_TYPE_EDGE_RISING>;

			reg = <0x1885008 0x8>,
			      <0x1885010 0x4>;
			reg-names = "qcom,spss-addr",
				    "qcom,spss-size";

			label = "spss";
			qcom,glink-label = "spss";
		};
	};

	qcom,trustedvm@d0800000 {
		status = "ok";
		qcom,pas-id = <28>;
		qcom,firmware-name = "trustedvm";
		memory-region = <&pil_trustedvm_mem>;
	};

	qcom,guestvm_loader {
		image_to_be_loaded = "trustedvm";
		qcom,reserved-cpus = <4 5>;
		qcom,unisolate-timeout-ms = <8000>;
	};

	ssc_sensors: qcom,msm-ssc-sensors {
		compatible = "qcom,msm-ssc-sensors";
		status = "ok";
		qcom,firmware-name = "slpi";
		qcom,rproc-handle = <&slpi_pas>;
	};

	qcom_tzlog: tz-log@146bf720 {
		compatible = "qcom,tz-log";
		reg = <0x146bf720 0x3000>;
		qcom,hyplog-enabled;
		hyplog-address-offset = <0x410>;
		hyplog-size-offset = <0x414>;
	};

	qcom_qseecom: qseecom@c1700000 {
		compatible = "qcom,qseecom";
		memory-region = <&qseecom_mem>;
		qseecom_mem = <&qseecom_mem>;
		qseecom_ta_mem = <&qseecom_ta_mem>;
		user_contig_mem = <&user_contig_mem>;
		qcom,hlos-num-ce-hw-instances = <1>;
		qcom,hlos-ce-hw-instance = <0>;
		qcom,qsee-ce-hw-instance = <0>;
		qcom,disk-encrypt-pipe-pair = <2>;
		qcom,support-fde;
		qcom,fde-key-size;
		qcom,no-clock-support;
		qcom,appsbl-qseecom-support;
		qcom,commonlib64-loaded-by-uefi;
		qcom,qsee-reentrancy-support = <2>;
	};

	qcom,spcom {
		compatible = "qcom,spcom";
		qcom,rproc-handle = <&spss_pas>;

		/* predefined channels, remote side is server */
		qcom,spcom-ch-names = "sp_kernel", "sp_ssr";
		/* sp2soc rmb shared register physical address and bmsk */
		qcom,spcom-sp2soc-rmb-reg-addr = <0x01881020>;
		qcom,spcom-sp2soc-rmb-initdone-bit = <24>;
		qcom,spcom-sp2soc-rmb-pbldone-bit = <25>;
		/* soc2sp rmb shared register physical address */
		qcom,spcom-soc2sp-rmb-reg-addr = <0x01881030>;
		qcom,spcom-soc2sp-rmb-sp-ssr-bit = <0>;
		qcom,boot-enabled;
		status = "ok";

		vreg_sp-supply = <&spss_vreg>;
		gpio_sp-supply = <&spss_gpio_vreg>;
	};

	spss_utils: qcom,spss_utils {
		compatible = "qcom,spss-utils";
		/* spss fuses physical address */
		qcom,rproc-handle = <&spss_pas>;
		qcom,spss-fuse1-addr = <0x00780204>;
		qcom,spss-fuse1-bit = <9>;
		qcom,spss-fuse2-addr = <0x00780204>;
		qcom,spss-fuse2-bit = <8>;
		qcom,spss-fuse3-addr = <0x007801C0>; // IAR_FEATURE_ENABLED fuse
		qcom,spss-fuse3-bit = <10>;
		qcom,spss-fuse4-addr = <0x00780204>; // IAR_STATE fuse
		qcom,spss-fuse4-bit = <25>; // 0x00780204 bits 25-27
		qcom,spss-dev-firmware-name  = "spss1d.mdt";  /* 8 chars max */
		qcom,spss-test-firmware-name = "spss1t.mdt";  /* 8 chars max */
		qcom,spss-prod-firmware-name = "spss1p.mdt";  /* 8 chars max */
		qcom,spss-debug-reg-addr = <0x01886020>;
		qcom,spss-scsr-regs-addr = <0x01880000>;  /* SPU shared register */
		qcom,spss-emul-type-reg-addr = <0x01fc8004>;
		pil-mem = <&pil_spss_mem>;
		qcom,pil-size = <0x0F0000>; // padding to 960 KB
		status = "ok";
	};

	eud: qcom,msm-eud@88e0000 {
		compatible = "qcom,msm-eud";
		interrupt-names = "eud_irq";
		interrupt-parent = <&pdc>;
		interrupts = <11 IRQ_TYPE_LEVEL_HIGH>;
		reg = <0x088E0000 0x2000>,
			<0x088E2000 0x1000>;
		reg-names = "eud_base", "eud_mode_mgr2";
		qcom,secure-eud-en;
		status = "ok";
	};

	qcom_cedev: qcedev@1de0000 {
		compatible = "qcom,qcedev";
		reg = <0x1de0000 0x20000>,
			<0x1dc4000 0x24000>;
		reg-names = "crypto-base","crypto-bam-base";
		interrupts = <GIC_SPI 272 IRQ_TYPE_LEVEL_HIGH>;
		qcom,bam-pipe-pair = <3>;
		qcom,ce-hw-instance = <0>;
		qcom,ce-device = <0>;
		qcom,ce-hw-shared;
		qcom,bam-ee = <0>;
		qcom,smmu-s1-enable;
		qcom,no-clock-support;
		interconnect-names = "data_path";
		interconnects = <&aggre2_noc MASTER_CRYPTO &mc_virt SLAVE_EBI1>;
		iommus = <&apps_smmu 0x0586 0x0011>,
			 <&apps_smmu 0x0596 0x0011>;
		qcom,iommu-dma = "atomic";

		qcom_cedev_ns_cb {
			compatible = "qcom,qcedev,context-bank";
			label = "ns_context";
			iommus = <&apps_smmu 0x592 0>,
				 <&apps_smmu 0x598 0>,
				 <&apps_smmu 0x599 0>,
				 <&apps_smmu 0x59F 0>;
		};

		qcom_cedev_s_cb {
			compatible = "qcom,qcedev,context-bank";
			label = "secure_context";
			iommus = <&apps_smmu 0x593 0>,
				 <&apps_smmu 0x59C 0>,
				 <&apps_smmu 0x59D 0>,
				 <&apps_smmu 0x59E 0>;
			qcom,iommu-vmid = <0x9>; /* VMID_CP_BITSTREAM */
			qcom,secure-context-bank;
		};
	};

	rng: rng@10d4000 {
		compatible = "qcom,trng";
		reg = <0x10d4000 0x1000>;
	};

	qcom_crypto: qcrypto@1de0000 {
		compatible = "qcom,qcrypto";
		reg = <0x1de0000 0x20000>,
			 <0x1dc4000 0x24000>;
		reg-names = "crypto-base","crypto-bam-base";
		interrupts = <GIC_SPI 272 IRQ_TYPE_LEVEL_HIGH>;
		qcom,bam-pipe-pair = <2>;
		qcom,ce-hw-instance = <0>;
		qcom,ce-device = <0>;
		qcom,bam-ee = <0>;
		qcom,ce-hw-shared;
		qcom,clk-mgmt-sus-res;
		qcom,use-sw-aes-cbc-ecb-ctr-algo;
		qcom,use-sw-aes-xts-algo;
		qcom,use-sw-aes-ccm-algo;
		qcom,use-sw-ahash-algo;
		qcom,use-sw-aead-algo;
		qcom,use-sw-hmac-algo;
		qcom,smmu-s1-enable;
		qcom,no-clock-support;
		interconnect-names = "data_path";
		interconnects = <&aggre2_noc MASTER_CRYPTO &mc_virt SLAVE_EBI1>;
		iommus = <&apps_smmu 0x0584 0x0011>,
			 <&apps_smmu 0x0594 0x0011>;
		qcom,iommu-dma = "atomic";
	};

	qcom,pmic_glink {
		compatible = "qcom,qti-pmic-glink";
		qcom,pmic-glink-channel = "PMIC_RTR_ADSP_APPS";
		qcom,subsys-name = "adsp";
		qcom,protection-domain = "tms/servreg", "msm/adsp/charger_pd";

		battery_charger: qcom,battery_charger {
			compatible = "qcom,battery-charger";
		};

		ucsi: qcom,ucsi {
			compatible = "qcom,ucsi-glink";
		};

		altmode: qcom,altmode {
			compatible = "qcom,altmode-glink";
			#altmode-cells = <1>;
		};
	};

	qcom,pmic_glink_log {
		compatible = "qcom,qti-pmic-glink";
		qcom,pmic-glink-channel = "PMIC_LOGS_ADSP_APPS";

		qcom,battery_debug {
			compatible = "qcom,battery-debug";
		};

		spmi_glink_debug: qcom,spmi_glink_debug {
			compatible = "qcom,spmi-glink-debug";
			#address-cells = <1>;
			#size-cells = <0>;
			status = "disabled";

			/* Primary SPMI bus */
			spmi@0 {
				reg = <0>;
				#address-cells = <2>;
				#size-cells = <0>;

				qcom,pm8350b-debug@3 {
					compatible = "qcom,spmi-pmic";
					reg = <3 SPMI_USID>;
					qcom,can-sleep;
				};
			};

			/* Secondary (QUP) SPMI bus */
			spmi@1 {
				reg = <1>;
				#address-cells = <2>;
				#size-cells = <0>;

				qcom,smb1396-debug@b {
					compatible = "qcom,spmi-pmic";
					reg = <11 SPMI_USID>;
					qcom,can-sleep;
				};

				qcom,smb1396-debug@c {
					compatible = "qcom,spmi-pmic";
					reg = <12 SPMI_USID>;
					qcom,can-sleep;
				};

				smb1398_debug: qcom,smb1398-debug@d {
					compatible = "qcom,spmi-pmic";
					reg = <13 SPMI_USID>;
					qcom,can-sleep;
					status = "disabled";
				};
			};
		};
	};

	bluetooth: bt_qca6490 {
		compatible = "qcom,qca6490";
		reg = <0xb2e5510 0x690>;
		reg-names = "tcs_cmd";
		pinctrl-names = "default";
		pinctrl-0 = <&bt_en_sleep>;
		/* offset=(0xC8*6) + (0x10*2) */
		qcom,tcs_offset_ipa = <0x4D0>;
		qcom,bt-reset-gpio = <&tlmm 65 0>; /* BT_EN */
		qcom,wl-reset-gpio = <&tlmm 64 0>; /* WL_EN */
		qcom,bt-sw-ctrl-gpio = <&tlmm 153 0>; /* SW_CTRL */
		qcom,bt-vdd-aon-supply = <&S11B>;
		qcom,bt-vdd-dig-supply = <&S11B>;
		qcom,bt-vdd-rfa1-supply = <&S1C>;
		qcom,bt-vdd-rfa2-supply = <&S12B>;
		qcom,bt-vdd-asd-supply = <&L7E>;

		qcom,bt-vdd-aon-config = <1012000 1012000 0 1>;
		qcom,bt-vdd-dig-config = <1012000 1012000 0 1>;
		qcom,bt-vdd-rfa1-config = <1900000 1952000 0 1>;
		qcom,bt-vdd-rfa2-config = <1350000 1360000 0 1>;
		qcom,bt-vdd-asd-config = <2800000 2800000 0 1>;
	};

	wil6210: qcom,wil6210 {
		compatible = "qcom,wil6210";
		qcom,pcie-parent = <&pcie1>;
		qcom,wigig-en = <&tlmm 47 0>;
		pinctrl-names = "default";
		pinctrl-0 = <&wil6210_refclk_en_pin>;
		qcom,11ad-bus-bw,name = "wil6210";
		qcom,11ad-bus-bw,num-cases = <3>;
		qcom,11ad-bus-bw,num-paths = <1>;
		qcom,11ad-bus-bw,vectors-KBps =
			<100 512 0 0>,
			<100 512 600000 800000>,  /* ~4.6Gbps (MCS12) */
			<100 512 1300000 1300000>; /* ~10.1Gbps */
		qcom,use-ext-supply;
		vdd-s1c-supply = <&S1C>;
		qcom,use-ext-clocks;
		clocks = <&rpmhcc RPMH_RF_CLK5>;
		clock-names = "rf_clk";
		qcom,keep-radio-on-during-sleep;
		qcom,use-ap-power-save;
		status = "disabled";
	};

	qfprom: qfprom@784000 {
		compatible = "qcom,qfprom";
		reg = <0x784000 0x3000>;
		#address-cells = <1>;
		#size-cells = <1>;
		read-only;
		ranges;

		gpu_speed_bin: gpu_speed_bin@17b {
				reg = <0x17b 0x1>;
				bits = <5 3>;
		};
	};
};

#include "ipcc-test.dtsi"
#include "lahaina-regulators.dtsi"
#include "lahaina-pinctrl.dtsi"
#include "lahaina-smp2p.dtsi"
#include "lahaina-dma-heaps.dtsi"
#include "msm-arm-smmu-lahaina.dtsi"
#include "lahaina-usb.dtsi"
#include "lahaina-coresight.dtsi"
#include "lahaina-pm.dtsi"
#include "lahaina-qupv3.dtsi"
#include "lahaina-pcie.dtsi"
#include "msm-qvr-external.dtsi"
#include "lahaina-debug.dtsi"

&pcie1_rp {
	#address-cells = <5>;
	#size-cells = <0>;

	wil6210_pci: wil6210_pci {
		reg = <0 0 0 0 0>;
		qcom,iommu-group = <&wil6210_pci_iommu_group>;

		#address-cells = <1>;
		#size-cells = <1>;

		wil6210_pci_iommu_group: wil6210_pci_iommu_group {
			reg = <0 0>;
			qcom,iommu-dma-addr-pool = <0x60000000 0xa0000000>;
			qcom,iommu-dma = "fastmap";
			qcom,iommu-pagetable = "coherent";
		};
	};
};

#include "lahaina-thermal.dtsi"

&qupv3_se18_4uart {
	status = "ok";
};

&qupv3_se13_i2c {
	status = "ok";
	nq@64 {
		compatible = "rtc6226";
		reg = <0x64>;
		fmint-gpio = <&tlmm 50 0>;
		vdd-supply = <&L7E>;
		rtc6226,vdd-supply-voltage = <2800000 2800000>;
		vio-supply = <&S10B>;
		rtc6226,vio-supply-voltage = <1800000 1800000 >;
	};

	fsa4480: fsa4480@42 {
		compatible = "qcom,fsa4480-i2c";
		reg = <0x42>;
	};
};

#include "msm-rdbg.dtsi"
#include "lahaina-walt.dtsi"
